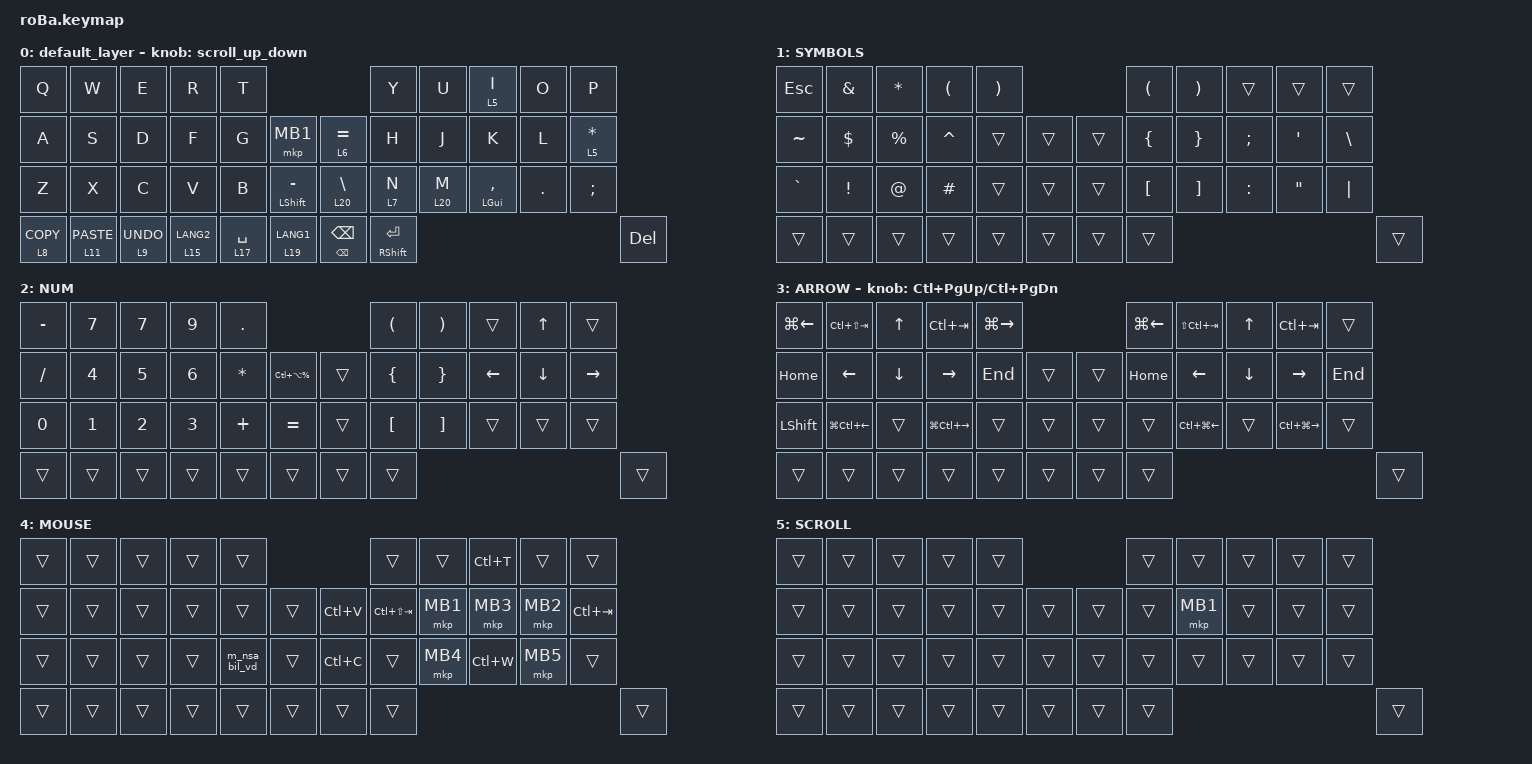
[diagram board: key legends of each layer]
#include <behaviors.dtsi>
#include <dt-bindings/zmk/bt.h>
#include <dt-bindings/zmk/keys.h>
#include <dt-bindings/zmk/pointing.h>

#undef ZMK_POINTING_DEFAULT_SCRL_VAL

#define ZMK_POINTING_DEFAULT_SCRL_VAL 100
#define MOUSE 4
#define SCROLL 5
#define NUM 6

&mt {
    flavor = "hold-preferred";
    quick-tap-ms = <200>;
};

&sl { release-after-ms = <250>; };

&trackball {
    automouse-layer = <4>;
    scroll-layers = <5>;
};

/ {
    combos {
        compatible = "zmk,combos";

        BT0 {
            bindings = <&bt BT_SEL 0>;
            key-positions = <28>;
        };

        BT1 {
            bindings = <&bt BT_SEL 1>;
            key-positions = <28 23>;
        };

        BT2 {
            bindings = <&bt BT_SEL 2>;
            key-positions = <28 24>;
        };

        combo_nsaffricate {
            timeout-ms = <150>;
            key-positions = <34 36>;
            bindings = <&ipa_sw 10 0>;
        };

        combo_saffricate {
            timeout-ms = <150>;
            key-positions = <34 35>;
            bindings = <&ipa_sw 12 0>;
        };

        combo_lfricative {
            timeout-ms = <150>;
            key-positions = <35 41>;
            bindings = <&ipa_sw 13 0>;
        };

        combo_laffricate {
            timeout-ms = <150>;
            key-positions = <34 35 41>;
            bindings = <&ipa_sw 14 0>;
        };

        combo_lapproximant {
            timeout-ms = <150>;
            key-positions = <37 41>;
            bindings = <&ipa_sw 16 0>;
        };

        combo_ltap {
            timeout-ms = <150>;
            key-positions = <38 41>;
            bindings = <&ipa_sw 18 0>;
        };

        // ==========================================
        // 追加: IPA ダイアクリティック用コンボ
        // ==========================================

        combo_SLA {
            timeout-ms = <300>;
            key-positions = <11 20 10>;
            bindings = <&mac_ipa_030D>;
        };

        combo_SLB {
            timeout-ms = <300>;
            key-positions = <11 20 26>;
            bindings = <&mac_ipa_0329>;
        };

        combo_NSA {
            timeout-ms = <300>;
            key-positions = <29 11 10>;
            bindings = <&mac_ipa_0311>;
        };

        combo_NSB {
            timeout-ms = <300>;
            key-positions = <29 11 26>;
            bindings = <&mac_ipa_032F>;
        };

        combo_HL {
            timeout-ms = <300>;
            key-positions = <17 20>;
            bindings = <&mac_ipa_02B0>;
        };

        combo_HHL {
            timeout-ms = <300>;
            key-positions = <17 17 20>;
            bindings = <&mac_ipa_02B1>;
        };

        combo_ML {
            timeout-ms = <300>;
            key-positions = <30 20>;
            bindings = <&mac_ipa_1D4D>;
        };

        combo_NL {
            timeout-ms = <300>;
            key-positions = <29 20>;
            bindings = <&mac_ipa_207F>;
        };

        combo_RNL {
            timeout-ms = <300>;
            key-positions = <3 29 20>;
            bindings = <&mac_ipa_1DAF>;
        };

        combo_GNL {
            timeout-ms = <300>;
            key-positions = <14 29 20>;
            bindings = <&mac_ipa_1DAE>;
        };

        combo_NGL {
            timeout-ms = <300>;
            key-positions = <29 14 20>;
            bindings = <&mac_ipa_1D51>;
        };

        combo_LL {
            timeout-ms = <300>;
            key-positions = <20 20>;
            bindings = <&mac_ipa_02E1>;
        };

        combo_AWL {
            timeout-ms = <300>;
            key-positions = <10 1 20>;
            bindings = <&mac_ipa_1D4A>;
        };

        combo_THL {
            timeout-ms = <300>;
            key-positions = <4 17 20>;
            bindings = <&mac_ipa_1DBF>;
        };

        combo_XL {
            timeout-ms = <300>;
            key-positions = <23 20>;
            bindings = <&mac_ipa_02E3>;
        };

        combo_AP {
            timeout-ms = <300>;
            key-positions = <10 9>;
            bindings = <&mac_ipa_031A>;
        };

        combo_VLA {
            timeout-ms = <300>;
            key-positions = <25 20 10>;
            bindings = <&mac_ipa_030A>;
        };

        combo_VLB {
            timeout-ms = <300>;
            key-positions = <25 20 26>;
            bindings = <&mac_ipa_0325>;
        };

        combo_VD {
            timeout-ms = <300>;
            key-positions = <25 12>;
            bindings = <&mac_ipa_032C>;
        };

        combo_TR {
            timeout-ms = <300>;
            key-positions = <4 3>;
            bindings = <&mac_ipa_0308>;
        };

        combo_TRB {
            timeout-ms = <300>;
            key-positions = <4 3 26>;
            bindings = <&mac_ipa_0324>;
        };

        combo_CT {
            timeout-ms = <300>;
            key-positions = <24 4>;
            bindings = <&mac_ipa_0308>;
        };

        combo_BVD {
            timeout-ms = <300>;
            key-positions = <26 25 12>;
            bindings = <&mac_ipa_0324>;
        };

        combo_TLA {
            timeout-ms = <300>;
            key-positions = <4 20 10>;
            bindings = <&mac_ipa_0303>;
        };

        combo_TLB {
            timeout-ms = <300>;
            key-positions = <4 20 26>;
            bindings = <&mac_ipa_0330>;
        };

        combo_NS {
            timeout-ms = <300>;
            key-positions = <29 11>;
            bindings = <&mac_ipa_0303>;
        };

        combo_CK {
            timeout-ms = <300>;
            key-positions = <24 19>;
            bindings = <&mac_ipa_0330>;
        };

        combo_DT_1 {
            timeout-ms = <300>;
            key-positions = <12 4>;
            bindings = <&mac_ipa_032A>;
        };

        combo_AC_1 {
            timeout-ms = <300>;
            key-positions = <10 24>;
            bindings = <&mac_ipa_033A>;
        };

        combo_FR {
            timeout-ms = <300>;
            key-positions = <13 3>;
            bindings = <&mac_ipa_031F>;
        };

        combo_BK {
            timeout-ms = <300>;
            key-positions = <26 19>;
            bindings = <&mac_ipa_0320>;
        };

        combo_PS {
            timeout-ms = <300>;
            key-positions = <9 11>;
            bindings = <&mac_ipa_031D>;
        };

        combo_DW {
            timeout-ms = <300>;
            key-positions = <12 1>;
            bindings = <&mac_ipa_031E>;
        };

        combo_LN {
            timeout-ms = <300>;
            key-positions = <20 29>;
            bindings = <&mac_ipa_033B>;
        };

        combo_LG {
            timeout-ms = <300>;
            key-positions = <20 14>;
            bindings = <&mac_ipa_033C>;
        };

        combo_MDC {
            timeout-ms = <300>;
            key-positions = <30 12 24>;
            bindings = <&mac_ipa_033D>;
        };

        combo_RDA {
            timeout-ms = <300>;
            key-positions = <3 12 10>;
            bindings = <&mac_ipa_0357>;
        };

        combo_RDB_1 {
            timeout-ms = <300>;
            key-positions = <3 12 26>;
            bindings = <&mac_ipa_0339>;
        };

        combo_URA {
            timeout-ms = <300>;
            key-positions = <6 3 10>;
            bindings = <&mac_ipa_0351>;
        };

        combo_URB {
            timeout-ms = <300>;
            key-positions = <6 3 26>;
            bindings = <&mac_ipa_031C>;
        };

        combo_WL {
            timeout-ms = <300>;
            key-positions = <1 20>;
            bindings = <&mac_ipa_02B7>;
        };

        combo_VL {
            timeout-ms = <300>;
            key-positions = <25 20>;
            bindings = <&mac_ipa_02E0>;
        };

        combo_GML {
            timeout-ms = <300>;
            key-positions = <14 30 20>;
            bindings = <&mac_ipa_02E0>;
        };

        combo_AL {
            timeout-ms = <300>;
            key-positions = <10 20>;
            bindings = <&mac_ipa_02E4>;
        };

        combo_HML {
            timeout-ms = <300>;
            key-positions = <17 30 20>;
            bindings = <&mac_ipa_02C0>;
        };

        combo_ATR {
            timeout-ms = <300>;
            key-positions = <10 4 3>;
            bindings = <&mac_ipa_0318>;
        };

        combo_RTR {
            timeout-ms = <300>;
            key-positions = <3 4 3>;
            bindings = <&mac_ipa_0319>;
        };

        combo_JL {
            timeout-ms = <300>;
            key-positions = <18 20>;
            bindings = <&mac_ipa_02B2>;
        };

        combo_LV {
            timeout-ms = <300>;
            key-positions = <20 25>;
            bindings = <&mac_ipa_026B>;
        };

        combo_RH {
            timeout-ms = <300>;
            key-positions = <3 17>;
            bindings = <&mac_ipa_02DE>;
        };

        combo_DIB {
            timeout-ms = <300>;
            key-positions = <12 7 26>;
            bindings = <&mac_ipa_0361>;
        };

        combo_DBB {
            timeout-ms = <300>;
            key-positions = <12 26 26>;
            bindings = <&mac_ipa_035C>;
        };

        combo_SP {
            timeout-ms = <300>;
            key-positions = <11 9>;
            bindings = <&mac_ipa_02C8>;
        };

        combo_SS {
            timeout-ms = <300>;
            key-positions = <11 11>;
            bindings = <&mac_ipa_02CC>;
        };

        combo_QQ {
            timeout-ms = <300>;
            key-positions = <0 0>;
            bindings = <&mac_ipa_02D0>;
        };

        combo_QQQ {
            timeout-ms = <300>;
            key-positions = <0 0 0>;
            bindings = <&mac_ipa_02D1>;
        };

        combo_FLA {
            timeout-ms = <300>;
            key-positions = <13 20 10>;
            bindings = <&mac_ipa_0306>;
        };

        combo_FLB {
            timeout-ms = <300>;
            key-positions = <13 20 26>;
            bindings = <&mac_ipa_032E>;
        };

        combo_BR {
            timeout-ms = <300>;
            key-positions = <26 3>;
            bindings = <&mac_ipa_0306>;
        };

        combo_BRB {
            timeout-ms = <300>;
            key-positions = <26 3 26>;
            bindings = <&mac_ipa_032E>;
        };

        combo_LK {
            timeout-ms = <300>;
            key-positions = <20 19>;
            bindings = <&mac_ipa_203F>;
        };

        combo_FB {
            timeout-ms = <300>;
            key-positions = <13 26>;
            bindings = <&mac_ipa_007C>;
        };

        combo_IB_1 {
            timeout-ms = <300>;
            key-positions = <7 26>;
            bindings = <&mac_ipa_2016>;
        };

        combo_GLR {
            timeout-ms = <300>;
            key-positions = <14 20 3>;
            bindings = <&mac_ipa_2197>;
        };

        combo_GLF {
            timeout-ms = <300>;
            key-positions = <14 20 13>;
            bindings = <&mac_ipa_2198>;
        };

        combo_PSS {
            timeout-ms = <300>;
            key-positions = <9 11 11>;
            bindings = <&mac_ipa_A71B>;
        };

        combo_DWS {
            timeout-ms = <300>;
            key-positions = <12 1 11>;
            bindings = <&mac_ipa_A71C>;
        };

        combo_AC_2 {
            timeout-ms = <300>;
            key-positions = <10 24>;
            bindings = <&mac_ipa_0301>;
        };

        combo_DAC {
            timeout-ms = <300>;
            key-positions = <12 10 24>;
            bindings = <&mac_ipa_030B>;
        };

        combo_GR {
            timeout-ms = <300>;
            key-positions = <14 3>;
            bindings = <&mac_ipa_0300>;
        };

        combo_DGR {
            timeout-ms = <300>;
            key-positions = <12 14 3>;
            bindings = <&mac_ipa_030F>;
        };

        combo_LT {
            timeout-ms = <300>;
            key-positions = <20 4>;
            bindings = <&mac_ipa_02E9>;
        };

        combo_HLT {
            timeout-ms = <300>;
            key-positions = <17 20 4>;
            bindings = <&mac_ipa_02E8>;
        };

        combo_MT {
            timeout-ms = <300>;
            key-positions = <30 4>;
            bindings = <&mac_ipa_02E7>;
        };

        combo_HHT {
            timeout-ms = <300>;
            key-positions = <17 17 4>;
            bindings = <&mac_ipa_02E6>;
        };

        combo_HT {
            timeout-ms = <300>;
            key-positions = <17 4>;
            bindings = <&mac_ipa_02E5>;
        };

        combo_MC {
            timeout-ms = <300>;
            key-positions = <30 24>;
            bindings = <&mac_ipa_0304>;
        };

        combo_MCB {
            timeout-ms = <300>;
            key-positions = <30 24 26>;
            bindings = <&mac_ipa_0331>;
        };

        combo_CR {
            timeout-ms = <300>;
            key-positions = <24 3>;
            bindings = <&mac_ipa_0302>;
        };

        combo_CRB {
            timeout-ms = <300>;
            key-positions = <24 3 26>;
            bindings = <&mac_ipa_032D>;
        };

        combo_HC {
            timeout-ms = <300>;
            key-positions = <17 24>;
            bindings = <&mac_ipa_030C>;
        };

        combo_HCB {
            timeout-ms = <300>;
            key-positions = <17 24 26>;
            bindings = <&mac_ipa_032C>;
        };

        combo_CD {
            timeout-ms = <300>;
            key-positions = <24 12>;
            bindings = <&mac_ipa_0327>;
        };

        combo_CM {
            timeout-ms = <300>;
            key-positions = <24 30>;
            bindings = <&mac_ipa_02BB>;
        };

        combo_CMB {
            timeout-ms = <300>;
            key-positions = <24 30 26>;
            bindings = <&mac_ipa_0326>;
        };

        combo_IB_2 {
            timeout-ms = <300>;
            key-positions = <7 26>;
            bindings = <&mac_ipa_0311>;
        };

        combo_IBB {
            timeout-ms = <300>;
            key-positions = <7 26 26>;
            bindings = <&mac_ipa_032F>;
        };

        combo_DT_2 {
            timeout-ms = <300>;
            key-positions = <12 4>;
            bindings = <&mac_ipa_0307>;
        };

        combo_DTB {
            timeout-ms = <300>;
            key-positions = <12 4 26>;
            bindings = <&mac_ipa_0323>;
        };

        combo_HK {
            timeout-ms = <300>;
            key-positions = <17 19>;
            bindings = <&mac_ipa_0309>;
        };

        combo_HR {
            timeout-ms = <300>;
            key-positions = <17 3>;
            bindings = <&mac_ipa_031B>;
        };

        combo_OG {
            timeout-ms = <300>;
            key-positions = <8 14>;
            bindings = <&mac_ipa_0328>;
        };

        combo_RG {
            timeout-ms = <300>;
            key-positions = <3 14>;
            bindings = <&mac_ipa_030A>;
        };

        combo_ST {
            timeout-ms = <300>;
            key-positions = <11 4>;
            bindings = <&mac_ipa_0335>;
        };

        combo_DK {
            timeout-ms = <300>;
            key-positions = <12 19>;
            bindings = <&mac_ipa_309B>;
        };

        combo_HD {
            timeout-ms = <300>;
            key-positions = <17 12>;
            bindings = <&mac_ipa_309C>;
        };

        combo_EJ {
            timeout-ms = <300>;
            key-positions = <2 18>;
            bindings = <&mac_ipa_02BC>;
        };

        combo_NM {
            timeout-ms = <300>;
            key-positions = <29 30>;
            bindings = <&mac_ipa_006E_0361_006D>;
        };

        combo_RNM {
            timeout-ms = <300>;
            key-positions = <3 29 30>;
            bindings = <&mac_ipa_0273_0361_006D>;
        };

        combo_NGM {
            timeout-ms = <300>;
            key-positions = <29 14 30>;
            bindings = <&mac_ipa_014B_0361_006D>;
        };

        combo_TP {
            timeout-ms = <300>;
            key-positions = <4 9>;
            bindings = <&mac_ipa_0074_0361_0070>;
        };

        combo_DB {
            timeout-ms = <300>;
            key-positions = <12 26>;
            bindings = <&mac_ipa_0064_0361_0062>;
        };

        combo_RTP {
            timeout-ms = <300>;
            key-positions = <3 4 9>;
            bindings = <&mac_ipa_0288_0361_0070>;
        };

        combo_RDB_2 {
            timeout-ms = <300>;
            key-positions = <3 12 26>;
            bindings = <&mac_ipa_0256_0361_0062>;
        };

        combo_KP {
            timeout-ms = <300>;
            key-positions = <19 9>;
            bindings = <&mac_ipa_006B_0361_0070>;
        };

        combo_GB {
            timeout-ms = <300>;
            key-positions = <14 26>;
            bindings = <&mac_ipa_0067_0361_0062>;
        };

        combo_QH {
            timeout-ms = <300>;
            key-positions = <0 17>;
            bindings = <&mac_ipa_0071_0361_02A1>;
        };

        combo_QP {
            timeout-ms = <300>;
            key-positions = <0 9>;
            bindings = <&mac_ipa_0071_0361_0070>;
        };

        combo_HYY {
            timeout-ms = <300>;
            key-positions = <17 5 5>;
            bindings = <&mac_ipa_0265_030A>;
        };

        combo_YY {
            timeout-ms = <300>;
            key-positions = <5 5>;
            bindings = <&mac_ipa_0265>;
        };

        combo_HW {
            timeout-ms = <300>;
            key-positions = <17 1>;
            bindings = <&mac_ipa_028D>;
        };

        combo_SJ {
            timeout-ms = <300>;
            key-positions = <11 18>;
            bindings = <&mac_ipa_0267>;
        };

        combo_MKP {
            timeout-ms = <300>;
            key-positions = <30 19 9>;
            bindings = <&mac_ipa_0260_030A_035C_0253_0325>;
        };

        combo_MGB {
            timeout-ms = <300>;
            key-positions = <30 14 26>;
            bindings = <&mac_ipa_0260_0361_0253>;
        };

        // ==========================================
        // IPA m_ and v_ macro combos
        // ==========================================

        // m_ macros: place of articulation + manner of articulation
        combo_m_nas_bil_vl { timeout-ms = <150>; key-positions = <9 29>; bindings = <&m_nas_bil_vl>; };
        combo_m_nas_bil_vd { timeout-ms = <150>; key-positions = <26 29>; bindings = <&m_nas_bil_vd>; };
        combo_m_nas_lab_vl { timeout-ms = <150>; key-positions = <13 29>; bindings = <&m_nas_lab_vl>; };
        combo_m_nas_lab_vd { timeout-ms = <150>; key-positions = <25 29>; bindings = <&m_nas_lab_vd>; };
        combo_m_nas_den_vl { timeout-ms = <150>; key-positions = <4 29>; bindings = <&m_nas_den_vl>; };
        combo_m_nas_den_vd { timeout-ms = <150>; key-positions = <12 29>; bindings = <&m_nas_den_vd>; };
        combo_m_nas_alv_vl { timeout-ms = <150>; key-positions = <11 29>; bindings = <&m_nas_alv_vl>; };
        combo_m_nas_alv_vd { timeout-ms = <150>; key-positions = <22 29>; bindings = <&m_nas_alv_vd>; };
        combo_m_nas_palv_vl { timeout-ms = <150>; key-positions = <23 29>; bindings = <&m_nas_palv_vl>; };
        combo_m_nas_palv_vd { timeout-ms = <150>; key-positions = <18 29>; bindings = <&m_nas_palv_vd>; };
        combo_m_nas_ret_vl { timeout-ms = <150>; key-positions = <20 29>; bindings = <&m_nas_ret_vl>; };
        combo_m_nas_ret_vd { timeout-ms = <150>; key-positions = <27 29>; bindings = <&m_nas_ret_vd>; };
        combo_m_nas_pala_vl { timeout-ms = <150>; key-positions = <24 29>; bindings = <&m_nas_pala_vl>; };
        combo_m_nas_pala_vd { timeout-ms = <150>; key-positions = <5 29>; bindings = <&m_nas_pala_vd>; };
        combo_m_nas_vel_vl { timeout-ms = <150>; key-positions = <19 29>; bindings = <&m_nas_vel_vl>; };
        combo_m_nas_vel_vd { timeout-ms = <150>; key-positions = <14 29>; bindings = <&m_nas_vel_vd>; };
        combo_m_nas_uv_vl { timeout-ms = <150>; key-positions = <0 29>; bindings = <&m_nas_uv_vl>; };
        combo_m_nas_uv_vd { timeout-ms = <150>; key-positions = <3 29>; bindings = <&m_nas_uv_vd>; };

        combo_m_p_bil_vl { timeout-ms = <150>; key-positions = <9 34>; bindings = <&m_p_bil_vl>; };
        combo_m_p_bil_vd { timeout-ms = <150>; key-positions = <26 34>; bindings = <&m_p_bil_vd>; };
        combo_m_p_lab_vl { timeout-ms = <150>; key-positions = <13 34>; bindings = <&m_p_lab_vl>; };
        combo_m_p_lab_vd { timeout-ms = <150>; key-positions = <25 34>; bindings = <&m_p_lab_vd>; };
        combo_m_p_den_vl { timeout-ms = <150>; key-positions = <4 34>; bindings = <&m_p_den_vl>; };
        combo_m_p_den_vd { timeout-ms = <150>; key-positions = <12 34>; bindings = <&m_p_den_vd>; };
        combo_m_p_alv_vl { timeout-ms = <150>; key-positions = <11 34>; bindings = <&m_p_alv_vl>; };
        combo_m_p_alv_vd { timeout-ms = <150>; key-positions = <22 34>; bindings = <&m_p_alv_vd>; };
        combo_m_p_ret_vl { timeout-ms = <150>; key-positions = <20 34>; bindings = <&m_p_ret_vl>; };
        combo_m_p_ret_vd { timeout-ms = <150>; key-positions = <27 34>; bindings = <&m_p_ret_vd>; };
        combo_m_p_pala_vl { timeout-ms = <150>; key-positions = <24 34>; bindings = <&m_p_pala_vl>; };
        combo_m_p_pala_vd { timeout-ms = <150>; key-positions = <5 34>; bindings = <&m_p_pala_vd>; };
        combo_m_p_vel_vl { timeout-ms = <150>; key-positions = <19 34>; bindings = <&m_p_vel_vl>; };
        combo_m_p_vel_vd { timeout-ms = <150>; key-positions = <14 34>; bindings = <&m_p_vel_vd>; };
        combo_m_p_uv_vl { timeout-ms = <150>; key-positions = <0 34>; bindings = <&m_p_uv_vl>; };
        combo_m_p_uv_vd { timeout-ms = <150>; key-positions = <3 34>; bindings = <&m_p_uv_vd>; };
        combo_m_p_epi_vl { timeout-ms = <150>; key-positions = <31 34>; bindings = <&m_p_epi_vl>; };
        combo_m_p_glo_vl { timeout-ms = <150>; key-positions = <33 34>; bindings = <&m_p_glo_vl>; };

        combo_m_nsf_bil_vl { timeout-ms = <150>; key-positions = <9 36>; bindings = <&m_nsf_bil_vl>; };
        combo_m_nsf_bil_vd { timeout-ms = <150>; key-positions = <26 36>; bindings = <&m_nsf_bil_vd>; };
        combo_m_nsf_lab_vl { timeout-ms = <150>; key-positions = <13 36>; bindings = <&m_nsf_lab_vl>; };
        combo_m_nsf_lab_vd { timeout-ms = <150>; key-positions = <25 36>; bindings = <&m_nsf_lab_vd>; };
        combo_m_nsf_den_vl { timeout-ms = <150>; key-positions = <4 36>; bindings = <&m_nsf_den_vl>; };
        combo_m_nsf_den_vd { timeout-ms = <150>; key-positions = <12 36>; bindings = <&m_nsf_den_vd>; };
        combo_m_nsf_alv_vl { timeout-ms = <150>; key-positions = <11 36>; bindings = <&m_nsf_alv_vl>; };
        combo_m_nsf_alv_vd { timeout-ms = <150>; key-positions = <22 36>; bindings = <&m_nsf_alv_vd>; };
        combo_m_nsf_palv_vl { timeout-ms = <150>; key-positions = <23 36>; bindings = <&m_nsf_palv_vl>; };
        combo_m_nsf_palv_vd { timeout-ms = <150>; key-positions = <18 36>; bindings = <&m_nsf_palv_vd>; };
        combo_m_nsf_ret_vl { timeout-ms = <150>; key-positions = <20 36>; bindings = <&m_nsf_ret_vl>; };
        combo_m_nsf_ret_vd { timeout-ms = <150>; key-positions = <27 36>; bindings = <&m_nsf_ret_vd>; };
        combo_m_nsf_pala_vl { timeout-ms = <150>; key-positions = <24 36>; bindings = <&m_nsf_pala_vl>; };
        combo_m_nsf_pala_vd { timeout-ms = <150>; key-positions = <5 36>; bindings = <&m_nsf_pala_vd>; };
        combo_m_nsf_vel_vl { timeout-ms = <150>; key-positions = <19 36>; bindings = <&m_nsf_vel_vl>; };
        combo_m_nsf_vel_vd { timeout-ms = <150>; key-positions = <14 36>; bindings = <&m_nsf_vel_vd>; };
        combo_m_nsf_uv_vl { timeout-ms = <150>; key-positions = <0 36>; bindings = <&m_nsf_uv_vl>; };
        combo_m_nsf_uv_vd { timeout-ms = <150>; key-positions = <3 36>; bindings = <&m_nsf_uv_vd>; };
        combo_m_nsf_epi_vl { timeout-ms = <150>; key-positions = <31 36>; bindings = <&m_nsf_epi_vl>; };
        combo_m_nsf_epi_vd { timeout-ms = <150>; key-positions = <32 36>; bindings = <&m_nsf_epi_vd>; };
        combo_m_nsf_glo_vl { timeout-ms = <150>; key-positions = <33 36>; bindings = <&m_nsf_glo_vl>; };
        combo_m_nsf_glo_vd { timeout-ms = <150>; key-positions = <17 36>; bindings = <&m_nsf_glo_vd>; };

        combo_m_nsa_bil_vl { timeout-ms = <150>; key-positions = <9 34 36>; bindings = <&m_nsa_bil_vl>; };
        combo_m_nsa_bil_vd { timeout-ms = <150>; key-positions = <26 34 36>; bindings = <&m_nsa_bil_vd>; };
        combo_m_nsa_lab_vl { timeout-ms = <150>; key-positions = <13 34 36>; bindings = <&m_nsa_lab_vl>; };
        combo_m_nsa_lab_vd { timeout-ms = <150>; key-positions = <25 34 36>; bindings = <&m_nsa_lab_vd>; };
        combo_m_nsa_den_vl { timeout-ms = <150>; key-positions = <4 34 36>; bindings = <&m_nsa_den_vl>; };
        combo_m_nsa_den_vd { timeout-ms = <150>; key-positions = <12 34 36>; bindings = <&m_nsa_den_vd>; };
        combo_m_nsa_alv_vl { timeout-ms = <150>; key-positions = <11 34 36>; bindings = <&m_nsa_alv_vl>; };
        combo_m_nsa_alv_vd { timeout-ms = <150>; key-positions = <22 34 36>; bindings = <&m_nsa_alv_vd>; };
        combo_m_nsa_palv_vl { timeout-ms = <150>; key-positions = <23 34 36>; bindings = <&m_nsa_palv_vl>; };
        combo_m_nsa_palv_vd { timeout-ms = <150>; key-positions = <18 34 36>; bindings = <&m_nsa_palv_vd>; };
        combo_m_nsa_ret_vl { timeout-ms = <150>; key-positions = <20 34 36>; bindings = <&m_nsa_ret_vl>; };
        combo_m_nsa_ret_vd { timeout-ms = <150>; key-positions = <27 34 36>; bindings = <&m_nsa_ret_vd>; };
        combo_m_nsa_pala_vl { timeout-ms = <150>; key-positions = <24 34 36>; bindings = <&m_nsa_pala_vl>; };
        combo_m_nsa_pala_vd { timeout-ms = <150>; key-positions = <5 34 36>; bindings = <&m_nsa_pala_vd>; };
        combo_m_nsa_vel_vl { timeout-ms = <150>; key-positions = <19 34 36>; bindings = <&m_nsa_vel_vl>; };
        combo_m_nsa_vel_vd { timeout-ms = <150>; key-positions = <14 34 36>; bindings = <&m_nsa_vel_vd>; };
        combo_m_nsa_uv_vl { timeout-ms = <150>; key-positions = <0 34 36>; bindings = <&m_nsa_uv_vl>; };
        combo_m_nsa_uv_vd { timeout-ms = <150>; key-positions = <3 34 36>; bindings = <&m_nsa_uv_vd>; };
        combo_m_nsa_epi_vl { timeout-ms = <150>; key-positions = <31 34 36>; bindings = <&m_nsa_epi_vl>; };
        combo_m_nsa_epi_vd { timeout-ms = <150>; key-positions = <32 34 36>; bindings = <&m_nsa_epi_vd>; };
        combo_m_nsa_glo_vl { timeout-ms = <150>; key-positions = <33 34 36>; bindings = <&m_nsa_glo_vl>; };

        combo_m_sf_den_vl { timeout-ms = <150>; key-positions = <4 35>; bindings = <&m_sf_den_vl>; };
        combo_m_sf_den_vd { timeout-ms = <150>; key-positions = <12 35>; bindings = <&m_sf_den_vd>; };
        combo_m_sf_alv_vl { timeout-ms = <150>; key-positions = <11 35>; bindings = <&m_sf_alv_vl>; };
        combo_m_sf_alv_vd { timeout-ms = <150>; key-positions = <22 35>; bindings = <&m_sf_alv_vd>; };
        combo_m_sf_palv_vl { timeout-ms = <150>; key-positions = <23 35>; bindings = <&m_sf_palv_vl>; };
        combo_m_sf_palv_vd { timeout-ms = <150>; key-positions = <18 35>; bindings = <&m_sf_palv_vd>; };
        combo_m_sf_ret_vl { timeout-ms = <150>; key-positions = <20 35>; bindings = <&m_sf_ret_vl>; };
        combo_m_sf_ret_vd { timeout-ms = <150>; key-positions = <27 35>; bindings = <&m_sf_ret_vd>; };
        combo_m_sf_pala_vl { timeout-ms = <150>; key-positions = <24 35>; bindings = <&m_sf_pala_vl>; };
        combo_m_sf_pala_vd { timeout-ms = <150>; key-positions = <5 35>; bindings = <&m_sf_pala_vd>; };

        combo_m_sa_den_vl { timeout-ms = <150>; key-positions = <4 34 35>; bindings = <&m_sa_den_vl>; };
        combo_m_sa_den_vd { timeout-ms = <150>; key-positions = <12 34 35>; bindings = <&m_sa_den_vd>; };
        combo_m_sa_alv_vl { timeout-ms = <150>; key-positions = <11 34 35>; bindings = <&m_sa_alv_vl>; };
        combo_m_sa_alv_vd { timeout-ms = <150>; key-positions = <22 34 35>; bindings = <&m_sa_alv_vd>; };
        combo_m_sa_palv_vl { timeout-ms = <150>; key-positions = <23 34 35>; bindings = <&m_sa_palv_vl>; };
        combo_m_sa_palv_vd { timeout-ms = <150>; key-positions = <18 34 35>; bindings = <&m_sa_palv_vd>; };
        combo_m_sa_pala_vl { timeout-ms = <150>; key-positions = <24 34 35>; bindings = <&m_sa_pala_vl>; };
        combo_m_sa_pala_vd { timeout-ms = <150>; key-positions = <5 34 35>; bindings = <&m_sa_pala_vd>; };
        combo_m_sa_ret_vl { timeout-ms = <150>; key-positions = <20 34 35>; bindings = <&m_sa_ret_vl>; };
        combo_m_sa_ret_vd { timeout-ms = <150>; key-positions = <27 34 35>; bindings = <&m_sa_ret_vd>; };

        combo_m_lf_den_vl { timeout-ms = <150>; key-positions = <4 35 41>; bindings = <&m_lf_den_vl>; };
        combo_m_lf_den_vd { timeout-ms = <150>; key-positions = <12 35 41>; bindings = <&m_lf_den_vd>; };
        combo_m_lf_alv_vl { timeout-ms = <150>; key-positions = <11 35 41>; bindings = <&m_lf_alv_vl>; };
        combo_m_lf_alv_vd { timeout-ms = <150>; key-positions = <22 35 41>; bindings = <&m_lf_alv_vd>; };
        combo_m_lf_ret_vl { timeout-ms = <150>; key-positions = <20 35 41>; bindings = <&m_lf_ret_vl>; };
        combo_m_lf_ret_vd { timeout-ms = <150>; key-positions = <27 35 41>; bindings = <&m_lf_ret_vd>; };
        combo_m_lf_pala_vl { timeout-ms = <150>; key-positions = <24 35 41>; bindings = <&m_lf_pala_vl>; };
        combo_m_lf_pala_vd { timeout-ms = <150>; key-positions = <5 35 41>; bindings = <&m_lf_pala_vd>; };
        combo_m_lf_vel_vl { timeout-ms = <150>; key-positions = <19 35 41>; bindings = <&m_lf_vel_vl>; };
        combo_m_lf_vel_vd { timeout-ms = <150>; key-positions = <14 35 41>; bindings = <&m_lf_vel_vd>; };

        combo_m_la_alv_vl { timeout-ms = <150>; key-positions = <11 34 35 41>; bindings = <&m_la_alv_vl>; };
        combo_m_la_alv_vd { timeout-ms = <150>; key-positions = <22 34 35 41>; bindings = <&m_la_alv_vd>; };
        combo_m_la_ret_vl { timeout-ms = <150>; key-positions = <20 34 35 41>; bindings = <&m_la_ret_vl>; };
        combo_m_la_ret_vd { timeout-ms = <150>; key-positions = <27 34 35 41>; bindings = <&m_la_ret_vd>; };
        combo_m_la_pala_vl { timeout-ms = <150>; key-positions = <24 34 35 41>; bindings = <&m_la_pala_vl>; };
        combo_m_la_pala_vd { timeout-ms = <150>; key-positions = <5 34 35 41>; bindings = <&m_la_pala_vd>; };
        combo_m_la_vel_vl { timeout-ms = <150>; key-positions = <19 34 35 41>; bindings = <&m_la_vel_vl>; };
        combo_m_la_vel_vd { timeout-ms = <150>; key-positions = <14 34 35 41>; bindings = <&m_la_vel_vd>; };

        combo_m_ap_bil_vd { timeout-ms = <150>; key-positions = <26 37>; bindings = <&m_ap_bil_vd>; };
        combo_m_ap_lab_vd { timeout-ms = <150>; key-positions = <25 37>; bindings = <&m_ap_lab_vd>; };
        combo_m_ap_den_vd { timeout-ms = <150>; key-positions = <12 37>; bindings = <&m_ap_den_vd>; };
        combo_m_ap_alv_vd { timeout-ms = <150>; key-positions = <22 37>; bindings = <&m_ap_alv_vd>; };
        combo_m_ap_palv_vd { timeout-ms = <150>; key-positions = <18 37>; bindings = <&m_ap_palv_vd>; };
        combo_m_ap_ret_vd { timeout-ms = <150>; key-positions = <27 37>; bindings = <&m_ap_ret_vd>; };
        combo_m_ap_pala_vd { timeout-ms = <150>; key-positions = <5 37>; bindings = <&m_ap_pala_vd>; };
        combo_m_ap_vel_vd { timeout-ms = <150>; key-positions = <14 37>; bindings = <&m_ap_vel_vd>; };

        combo_m_lap_den_vd { timeout-ms = <150>; key-positions = <12 37 41>; bindings = <&m_lap_den_vd>; };
        combo_m_lap_alv_vl { timeout-ms = <150>; key-positions = <11 37 41>; bindings = <&m_lap_alv_vl>; };
        combo_m_lap_alv_vd { timeout-ms = <150>; key-positions = <22 37 41>; bindings = <&m_lap_alv_vd>; };
        combo_m_lap_ret_vl { timeout-ms = <150>; key-positions = <20 37 41>; bindings = <&m_lap_ret_vl>; };
        combo_m_lap_ret_vd { timeout-ms = <150>; key-positions = <27 37 41>; bindings = <&m_lap_ret_vd>; };
        combo_m_lap_pala_vl { timeout-ms = <150>; key-positions = <24 37 41>; bindings = <&m_lap_pala_vl>; };
        combo_m_lap_pala_vd { timeout-ms = <150>; key-positions = <5 37 41>; bindings = <&m_lap_pala_vd>; };
        combo_m_lap_vel_vl { timeout-ms = <150>; key-positions = <19 37 41>; bindings = <&m_lap_vel_vl>; };
        combo_m_lap_vel_vd { timeout-ms = <150>; key-positions = <14 37 41>; bindings = <&m_lap_vel_vd>; };
        combo_m_lap_uv_vd { timeout-ms = <150>; key-positions = <3 37 41>; bindings = <&m_lap_uv_vd>; };

        combo_m_tap_lab_vd { timeout-ms = <150>; key-positions = <25 38>; bindings = <&m_tap_lab_vd>; };
        combo_m_tap_alv_vl { timeout-ms = <150>; key-positions = <11 38>; bindings = <&m_tap_alv_vl>; };
        combo_m_tap_alv_vd { timeout-ms = <150>; key-positions = <22 38>; bindings = <&m_tap_alv_vd>; };
        combo_m_tap_ret_vl { timeout-ms = <150>; key-positions = <20 38>; bindings = <&m_tap_ret_vl>; };
        combo_m_tap_ret_vd { timeout-ms = <150>; key-positions = <27 38>; bindings = <&m_tap_ret_vd>; };
        combo_m_tap_uv_vd { timeout-ms = <150>; key-positions = <3 38>; bindings = <&m_tap_uv_vd>; };
        combo_m_tap_epi_vd { timeout-ms = <150>; key-positions = <31 38>; bindings = <&m_tap_epi_vd>; };

        combo_m_ltap_alv_vl { timeout-ms = <150>; key-positions = <11 38 41>; bindings = <&m_ltap_alv_vl>; };
        combo_m_ltap_alv_vd { timeout-ms = <150>; key-positions = <22 38 41>; bindings = <&m_ltap_alv_vd>; };
        combo_m_ltap_ret_vl { timeout-ms = <150>; key-positions = <20 38 41>; bindings = <&m_ltap_ret_vl>; };
        combo_m_ltap_ret_vd { timeout-ms = <150>; key-positions = <27 38 41>; bindings = <&m_ltap_ret_vd>; };
        combo_m_ltap_pala_vd { timeout-ms = <150>; key-positions = <5 38 41>; bindings = <&m_ltap_pala_vd>; };
        combo_m_ltap_vel_vd { timeout-ms = <150>; key-positions = <14 38 41>; bindings = <&m_ltap_vel_vd>; };

        combo_m_tr_bil_vl { timeout-ms = <150>; key-positions = <9 39>; bindings = <&m_tr_bil_vl>; };
        combo_m_tr_bil_vd { timeout-ms = <150>; key-positions = <26 39>; bindings = <&m_tr_bil_vd>; };
        combo_m_tr_alv_vl { timeout-ms = <150>; key-positions = <11 39>; bindings = <&m_tr_alv_vl>; };
        combo_m_tr_alv_vd { timeout-ms = <150>; key-positions = <22 39>; bindings = <&m_tr_alv_vd>; };
        combo_m_tr_palv_vd { timeout-ms = <150>; key-positions = <18 39>; bindings = <&m_tr_palv_vd>; };
        combo_m_tr_ret_vl { timeout-ms = <150>; key-positions = <20 39>; bindings = <&m_tr_ret_vl>; };
        combo_m_tr_ret_vd { timeout-ms = <150>; key-positions = <27 39>; bindings = <&m_tr_ret_vd>; };
        combo_m_tr_uv_vl { timeout-ms = <150>; key-positions = <0 39>; bindings = <&m_tr_uv_vl>; };
        combo_m_tr_uv_vd { timeout-ms = <150>; key-positions = <3 39>; bindings = <&m_tr_uv_vd>; };
        combo_m_tr_epi_vl { timeout-ms = <150>; key-positions = <31 39>; bindings = <&m_tr_epi_vl>; };
        combo_m_tr_epi_vd { timeout-ms = <150>; key-positions = <32 39>; bindings = <&m_tr_epi_vd>; };

        combo_m_im_bil_vl { timeout-ms = <150>; key-positions = <9 30>; bindings = <&m_im_bil_vl>; };
        combo_m_im_bil_vd { timeout-ms = <150>; key-positions = <26 30>; bindings = <&m_im_bil_vd>; };
        combo_m_im_den_vl { timeout-ms = <150>; key-positions = <4 30>; bindings = <&m_im_den_vl>; };
        combo_m_im_alv_vl { timeout-ms = <150>; key-positions = <11 30>; bindings = <&m_im_alv_vl>; };
        combo_m_im_alv_vd { timeout-ms = <150>; key-positions = <22 30>; bindings = <&m_im_alv_vd>; };
        combo_m_im_ret_vl { timeout-ms = <150>; key-positions = <20 30>; bindings = <&m_im_ret_vl>; };
        combo_m_im_ret_vd { timeout-ms = <150>; key-positions = <27 30>; bindings = <&m_im_ret_vd>; };
        combo_m_im_pala_vl { timeout-ms = <150>; key-positions = <24 30>; bindings = <&m_im_pala_vl>; };
        combo_m_im_pala_vd { timeout-ms = <150>; key-positions = <5 30>; bindings = <&m_im_pala_vd>; };
        combo_m_im_vel_vl { timeout-ms = <150>; key-positions = <19 30>; bindings = <&m_im_vel_vl>; };
        combo_m_im_vel_vd { timeout-ms = <150>; key-positions = <14 30>; bindings = <&m_im_vel_vd>; };
        combo_m_im_uv_vd { timeout-ms = <150>; key-positions = <3 30>; bindings = <&m_im_uv_vd>; };

        combo_m_lim_den_vl { timeout-ms = <150>; key-positions = <4 30 41>; bindings = <&m_lim_den_vl>; };

        // v_ macros: openness + frontness/roundedness
        combo_v_cl_fr_un { timeout-ms = <150>; key-positions = <34 7>; bindings = <&v_cl_fr_un>; };
        combo_v_cl_fr_ro { timeout-ms = <150>; key-positions = <34 8>; bindings = <&v_cl_fr_ro>; };
        combo_v_cl_ce_un { timeout-ms = <150>; key-positions = <34 10>; bindings = <&v_cl_ce_un>; };
        combo_v_cl_ce_ro { timeout-ms = <150>; key-positions = <34 1>; bindings = <&v_cl_ce_ro>; };
        combo_v_cl_ba_un { timeout-ms = <150>; key-positions = <34 2>; bindings = <&v_cl_ba_un>; };
        combo_v_cl_ba_ro { timeout-ms = <150>; key-positions = <34 6>; bindings = <&v_cl_ba_ro>; };

        combo_v_nc_fr_un { timeout-ms = <150>; key-positions = <35 7>; bindings = <&v_nc_fr_un>; };
        combo_v_nc_fr_ro { timeout-ms = <150>; key-positions = <35 8>; bindings = <&v_nc_fr_ro>; };
        combo_v_nc_ce_un { timeout-ms = <150>; key-positions = <35 10>; bindings = <&v_nc_ce_un>; };
        combo_v_nc_ce_ro { timeout-ms = <150>; key-positions = <35 1>; bindings = <&v_nc_ce_ro>; };
        combo_v_nc_ba_un { timeout-ms = <150>; key-positions = <35 2>; bindings = <&v_nc_ba_un>; };
        combo_v_nc_ba_ro { timeout-ms = <150>; key-positions = <35 6>; bindings = <&v_nc_ba_ro>; };

        combo_v_cm_fr_un { timeout-ms = <150>; key-positions = <36 7>; bindings = <&v_cm_fr_un>; };
        combo_v_cm_fr_ro { timeout-ms = <150>; key-positions = <36 8>; bindings = <&v_cm_fr_ro>; };
        combo_v_cm_ce_un { timeout-ms = <150>; key-positions = <36 10>; bindings = <&v_cm_ce_un>; };
        combo_v_cm_ce_ro { timeout-ms = <150>; key-positions = <36 1>; bindings = <&v_cm_ce_ro>; };
        combo_v_cm_ba_un { timeout-ms = <150>; key-positions = <36 2>; bindings = <&v_cm_ba_un>; };
        combo_v_cm_ba_ro { timeout-ms = <150>; key-positions = <36 6>; bindings = <&v_cm_ba_ro>; };

        combo_v_mi_fr_un { timeout-ms = <150>; key-positions = <37 7>; bindings = <&v_mi_fr_un>; };
        combo_v_mi_fr_ro { timeout-ms = <150>; key-positions = <37 8>; bindings = <&v_mi_fr_ro>; };
        combo_v_mi_ce_un { timeout-ms = <150>; key-positions = <37 10>; bindings = <&v_mi_ce_un>; };
        combo_v_mi_ce_ro { timeout-ms = <150>; key-positions = <37 1>; bindings = <&v_mi_ce_ro>; };
        combo_v_mi_ba_un { timeout-ms = <150>; key-positions = <37 2>; bindings = <&v_mi_ba_un>; };
        combo_v_mi_ba_ro { timeout-ms = <150>; key-positions = <37 6>; bindings = <&v_mi_ba_ro>; };

        combo_v_om_fr_un { timeout-ms = <150>; key-positions = <38 7>; bindings = <&v_om_fr_un>; };
        combo_v_om_fr_ro { timeout-ms = <150>; key-positions = <38 8>; bindings = <&v_om_fr_ro>; };
        combo_v_om_ce_un { timeout-ms = <150>; key-positions = <38 10>; bindings = <&v_om_ce_un>; };
        combo_v_om_ce_ro { timeout-ms = <150>; key-positions = <38 1>; bindings = <&v_om_ce_ro>; };
        combo_v_om_ba_un { timeout-ms = <150>; key-positions = <38 2>; bindings = <&v_om_ba_un>; };
        combo_v_om_ba_ro { timeout-ms = <150>; key-positions = <38 6>; bindings = <&v_om_ba_ro>; };

        combo_v_no_fr_un { timeout-ms = <150>; key-positions = <39 7>; bindings = <&v_no_fr_un>; };
        combo_v_no_fr_ro { timeout-ms = <150>; key-positions = <39 8>; bindings = <&v_no_fr_ro>; };
        combo_v_no_ce_un { timeout-ms = <150>; key-positions = <39 10>; bindings = <&v_no_ce_un>; };
        combo_v_no_ce_ro { timeout-ms = <150>; key-positions = <39 1>; bindings = <&v_no_ce_ro>; };
        combo_v_no_ba_un { timeout-ms = <150>; key-positions = <39 2>; bindings = <&v_no_ba_un>; };
        combo_v_no_ba_ro { timeout-ms = <150>; key-positions = <39 6>; bindings = <&v_no_ba_ro>; };

        combo_v_op_fr_un { timeout-ms = <150>; key-positions = <28 7>; bindings = <&v_op_fr_un>; };
        combo_v_op_fr_ro { timeout-ms = <150>; key-positions = <28 8>; bindings = <&v_op_fr_ro>; };
        combo_v_op_ce_un { timeout-ms = <150>; key-positions = <28 10>; bindings = <&v_op_ce_un>; };
        combo_v_op_ce_ro { timeout-ms = <150>; key-positions = <28 1>; bindings = <&v_op_ce_ro>; };
        combo_v_op_ba_un { timeout-ms = <150>; key-positions = <28 2>; bindings = <&v_op_ba_un>; };
        combo_v_op_ba_ro { timeout-ms = <150>; key-positions = <28 6>; bindings = <&v_op_ba_ro>; };
    };

    macros {
        // ==========================================
        // IPA ダイアクリティック / 記号用マクロ群
        // ==========================================

        mac_ipa_030D: mac_ipa_030D {
            compatible = "zmk,behavior-macro";
            #binding-cells = <0>;
            wait-ms = <30>;             tap-ms = <30>;
            bindings = <&macro_press &kp LALT>, <&kp U &kp N0 &kp N3 &kp N0 &kp D>, <&macro_release &kp LALT>;
        };

        mac_ipa_0329: mac_ipa_0329 {
            compatible = "zmk,behavior-macro";
            #binding-cells = <0>;
            wait-ms = <30>;             tap-ms = <30>;
            bindings = <&macro_press &kp LALT>, <&kp U &kp N0 &kp N3 &kp N2 &kp N9>, <&macro_release &kp LALT>;
        };

        mac_ipa_0311: mac_ipa_0311 {
            compatible = "zmk,behavior-macro";
            #binding-cells = <0>;
            wait-ms = <30>;             tap-ms = <30>;
            bindings = <&macro_press &kp LALT>, <&kp U &kp N0 &kp N3 &kp N1 &kp N1>, <&macro_release &kp LALT>;
        };

        mac_ipa_032F: mac_ipa_032F {
            compatible = "zmk,behavior-macro";
            #binding-cells = <0>;
            wait-ms = <30>;             tap-ms = <30>;
            bindings = <&macro_press &kp LALT>, <&kp U &kp N0 &kp N3 &kp N2 &kp F>, <&macro_release &kp LALT>;
        };

        mac_ipa_02B0: mac_ipa_02B0 {
            compatible = "zmk,behavior-macro";
            #binding-cells = <0>;
            wait-ms = <30>;             tap-ms = <30>;
            bindings = <&macro_press &kp LALT>, <&kp U &kp N0 &kp N2 &kp B &kp N0>, <&macro_release &kp LALT>;
        };

        mac_ipa_02B1: mac_ipa_02B1 {
            compatible = "zmk,behavior-macro";
            #binding-cells = <0>;
            wait-ms = <30>;             tap-ms = <30>;
            bindings = <&macro_press &kp LALT>, <&kp U &kp N0 &kp N2 &kp B &kp N1>, <&macro_release &kp LALT>;
        };

        mac_ipa_1D4D: mac_ipa_1D4D {
            compatible = "zmk,behavior-macro";
            #binding-cells = <0>;
            wait-ms = <30>;             tap-ms = <30>;
            bindings = <&macro_press &kp LALT>, <&kp U &kp N1 &kp D &kp N4 &kp D>, <&macro_release &kp LALT>;
        };

        mac_ipa_207F: mac_ipa_207F {
            compatible = "zmk,behavior-macro";
            #binding-cells = <0>;
            wait-ms = <30>;             tap-ms = <30>;
            bindings = <&macro_press &kp LALT>, <&kp U &kp N2 &kp N0 &kp N7 &kp F>, <&macro_release &kp LALT>;
        };

        mac_ipa_1DAF: mac_ipa_1DAF {
            compatible = "zmk,behavior-macro";
            #binding-cells = <0>;
            wait-ms = <30>;             tap-ms = <30>;
            bindings = <&macro_press &kp LALT>, <&kp U &kp N1 &kp D &kp A &kp F>, <&macro_release &kp LALT>;
        };

        mac_ipa_1DAE: mac_ipa_1DAE {
            compatible = "zmk,behavior-macro";
            #binding-cells = <0>;
            wait-ms = <30>;             tap-ms = <30>;
            bindings = <&macro_press &kp LALT>, <&kp U &kp N1 &kp D &kp A &kp E>, <&macro_release &kp LALT>;
        };

        mac_ipa_1D51: mac_ipa_1D51 {
            compatible = "zmk,behavior-macro";
            #binding-cells = <0>;
            wait-ms = <30>;             tap-ms = <30>;
            bindings = <&macro_press &kp LALT>, <&kp U &kp N1 &kp D &kp N5 &kp N1>, <&macro_release &kp LALT>;
        };

        mac_ipa_02E1: mac_ipa_02E1 {
            compatible = "zmk,behavior-macro";
            #binding-cells = <0>;
            wait-ms = <30>;             tap-ms = <30>;
            bindings = <&macro_press &kp LALT>, <&kp U &kp N0 &kp N2 &kp E &kp N1>, <&macro_release &kp LALT>;
        };

        mac_ipa_1D4A: mac_ipa_1D4A {
            compatible = "zmk,behavior-macro";
            #binding-cells = <0>;
            wait-ms = <30>;             tap-ms = <30>;
            bindings = <&macro_press &kp LALT>, <&kp U &kp N1 &kp D &kp N4 &kp A>, <&macro_release &kp LALT>;
        };

        mac_ipa_1DBF: mac_ipa_1DBF {
            compatible = "zmk,behavior-macro";
            #binding-cells = <0>;
            wait-ms = <30>;             tap-ms = <30>;
            bindings = <&macro_press &kp LALT>, <&kp U &kp N1 &kp D &kp B &kp F>, <&macro_release &kp LALT>;
        };

        mac_ipa_02E3: mac_ipa_02E3 {
            compatible = "zmk,behavior-macro";
            #binding-cells = <0>;
            wait-ms = <30>;             tap-ms = <30>;
            bindings = <&macro_press &kp LALT>, <&kp U &kp N0 &kp N2 &kp E &kp N3>, <&macro_release &kp LALT>;
        };

        mac_ipa_031A: mac_ipa_031A {
            compatible = "zmk,behavior-macro";
            #binding-cells = <0>;
            wait-ms = <30>;             tap-ms = <30>;
            bindings = <&macro_press &kp LALT>, <&kp U &kp N0 &kp N3 &kp N1 &kp A>, <&macro_release &kp LALT>;
        };

        mac_ipa_030A: mac_ipa_030A {
            compatible = "zmk,behavior-macro";
            #binding-cells = <0>;
            wait-ms = <30>;             tap-ms = <30>;
            bindings = <&macro_press &kp LALT>, <&kp U &kp N0 &kp N3 &kp N0 &kp A>, <&macro_release &kp LALT>;
        };

        mac_ipa_0325: mac_ipa_0325 {
            compatible = "zmk,behavior-macro";
            #binding-cells = <0>;
            wait-ms = <30>;             tap-ms = <30>;
            bindings = <&macro_press &kp LALT>, <&kp U &kp N0 &kp N3 &kp N2 &kp N5>, <&macro_release &kp LALT>;
        };

        mac_ipa_032C: mac_ipa_032C {
            compatible = "zmk,behavior-macro";
            #binding-cells = <0>;
            wait-ms = <30>;             tap-ms = <30>;
            bindings = <&macro_press &kp LALT>, <&kp U &kp N0 &kp N3 &kp N2 &kp C>, <&macro_release &kp LALT>;
        };

        mac_ipa_0308: mac_ipa_0308 {
            compatible = "zmk,behavior-macro";
            #binding-cells = <0>;
            wait-ms = <30>;             tap-ms = <30>;
            bindings = <&macro_press &kp LALT>, <&kp U &kp N0 &kp N3 &kp N0 &kp N8>, <&macro_release &kp LALT>;
        };

        mac_ipa_0324: mac_ipa_0324 {
            compatible = "zmk,behavior-macro";
            #binding-cells = <0>;
            wait-ms = <30>;             tap-ms = <30>;
            bindings = <&macro_press &kp LALT>, <&kp U &kp N0 &kp N3 &kp N2 &kp N4>, <&macro_release &kp LALT>;
        };

        mac_ipa_0303: mac_ipa_0303 {
            compatible = "zmk,behavior-macro";
            #binding-cells = <0>;
            wait-ms = <30>;             tap-ms = <30>;
            bindings = <&macro_press &kp LALT>, <&kp U &kp N0 &kp N3 &kp N0 &kp N3>, <&macro_release &kp LALT>;
        };

        mac_ipa_0330: mac_ipa_0330 {
            compatible = "zmk,behavior-macro";
            #binding-cells = <0>;
            wait-ms = <30>;             tap-ms = <30>;
            bindings = <&macro_press &kp LALT>, <&kp U &kp N0 &kp N3 &kp N3 &kp N0>, <&macro_release &kp LALT>;
        };

        mac_ipa_032A: mac_ipa_032A {
            compatible = "zmk,behavior-macro";
            #binding-cells = <0>;
            wait-ms = <30>;             tap-ms = <30>;
            bindings = <&macro_press &kp LALT>, <&kp U &kp N0 &kp N3 &kp N2 &kp A>, <&macro_release &kp LALT>;
        };

        mac_ipa_033A: mac_ipa_033A {
            compatible = "zmk,behavior-macro";
            #binding-cells = <0>;
            wait-ms = <30>;             tap-ms = <30>;
            bindings = <&macro_press &kp LALT>, <&kp U &kp N0 &kp N3 &kp N3 &kp A>, <&macro_release &kp LALT>;
        };

        mac_ipa_031F: mac_ipa_031F {
            compatible = "zmk,behavior-macro";
            #binding-cells = <0>;
            wait-ms = <30>;             tap-ms = <30>;
            bindings = <&macro_press &kp LALT>, <&kp U &kp N0 &kp N3 &kp N1 &kp F>, <&macro_release &kp LALT>;
        };

        mac_ipa_0320: mac_ipa_0320 {
            compatible = "zmk,behavior-macro";
            #binding-cells = <0>;
            wait-ms = <30>;             tap-ms = <30>;
            bindings = <&macro_press &kp LALT>, <&kp U &kp N0 &kp N3 &kp N2 &kp N0>, <&macro_release &kp LALT>;
        };

        mac_ipa_031D: mac_ipa_031D {
            compatible = "zmk,behavior-macro";
            #binding-cells = <0>;
            wait-ms = <30>;             tap-ms = <30>;
            bindings = <&macro_press &kp LALT>, <&kp U &kp N0 &kp N3 &kp N1 &kp D>, <&macro_release &kp LALT>;
        };

        mac_ipa_031E: mac_ipa_031E {
            compatible = "zmk,behavior-macro";
            #binding-cells = <0>;
            wait-ms = <30>;             tap-ms = <30>;
            bindings = <&macro_press &kp LALT>, <&kp U &kp N0 &kp N3 &kp N1 &kp E>, <&macro_release &kp LALT>;
        };

        mac_ipa_033B: mac_ipa_033B {
            compatible = "zmk,behavior-macro";
            #binding-cells = <0>;
            wait-ms = <30>;             tap-ms = <30>;
            bindings = <&macro_press &kp LALT>, <&kp U &kp N0 &kp N3 &kp N3 &kp B>, <&macro_release &kp LALT>;
        };

        mac_ipa_033C: mac_ipa_033C {
            compatible = "zmk,behavior-macro";
            #binding-cells = <0>;
            wait-ms = <30>;             tap-ms = <30>;
            bindings = <&macro_press &kp LALT>, <&kp U &kp N0 &kp N3 &kp N3 &kp C>, <&macro_release &kp LALT>;
        };

        mac_ipa_033D: mac_ipa_033D {
            compatible = "zmk,behavior-macro";
            #binding-cells = <0>;
            wait-ms = <30>;             tap-ms = <30>;
            bindings = <&macro_press &kp LALT>, <&kp U &kp N0 &kp N3 &kp N3 &kp D>, <&macro_release &kp LALT>;
        };

        mac_ipa_0357: mac_ipa_0357 {
            compatible = "zmk,behavior-macro";
            #binding-cells = <0>;
            wait-ms = <30>;             tap-ms = <30>;
            bindings = <&macro_press &kp LALT>, <&kp U &kp N0 &kp N3 &kp N5 &kp N7>, <&macro_release &kp LALT>;
        };

        mac_ipa_0339: mac_ipa_0339 {
            compatible = "zmk,behavior-macro";
            #binding-cells = <0>;
            wait-ms = <30>;             tap-ms = <30>;
            bindings = <&macro_press &kp LALT>, <&kp U &kp N0 &kp N3 &kp N3 &kp N9>, <&macro_release &kp LALT>;
        };

        mac_ipa_0351: mac_ipa_0351 {
            compatible = "zmk,behavior-macro";
            #binding-cells = <0>;
            wait-ms = <30>;             tap-ms = <30>;
            bindings = <&macro_press &kp LALT>, <&kp U &kp N0 &kp N3 &kp N5 &kp N1>, <&macro_release &kp LALT>;
        };

        mac_ipa_031C: mac_ipa_031C {
            compatible = "zmk,behavior-macro";
            #binding-cells = <0>;
            wait-ms = <30>;             tap-ms = <30>;
            bindings = <&macro_press &kp LALT>, <&kp U &kp N0 &kp N3 &kp N1 &kp C>, <&macro_release &kp LALT>;
        };

        mac_ipa_02B7: mac_ipa_02B7 {
            compatible = "zmk,behavior-macro";
            #binding-cells = <0>;
            wait-ms = <30>;             tap-ms = <30>;
            bindings = <&macro_press &kp LALT>, <&kp U &kp N0 &kp N2 &kp B &kp N7>, <&macro_release &kp LALT>;
        };

        mac_ipa_02E0: mac_ipa_02E0 {
            compatible = "zmk,behavior-macro";
            #binding-cells = <0>;
            wait-ms = <30>;             tap-ms = <30>;
            bindings = <&macro_press &kp LALT>, <&kp U &kp N0 &kp N2 &kp E &kp N0>, <&macro_release &kp LALT>;
        };

        mac_ipa_02E4: mac_ipa_02E4 {
            compatible = "zmk,behavior-macro";
            #binding-cells = <0>;
            wait-ms = <30>;             tap-ms = <30>;
            bindings = <&macro_press &kp LALT>, <&kp U &kp N0 &kp N2 &kp E &kp N4>, <&macro_release &kp LALT>;
        };

        mac_ipa_02C0: mac_ipa_02C0 {
            compatible = "zmk,behavior-macro";
            #binding-cells = <0>;
            wait-ms = <30>;             tap-ms = <30>;
            bindings = <&macro_press &kp LALT>, <&kp U &kp N0 &kp N2 &kp C &kp N0>, <&macro_release &kp LALT>;
        };

        mac_ipa_0318: mac_ipa_0318 {
            compatible = "zmk,behavior-macro";
            #binding-cells = <0>;
            wait-ms = <30>;             tap-ms = <30>;
            bindings = <&macro_press &kp LALT>, <&kp U &kp N0 &kp N3 &kp N1 &kp N8>, <&macro_release &kp LALT>;
        };

        mac_ipa_0319: mac_ipa_0319 {
            compatible = "zmk,behavior-macro";
            #binding-cells = <0>;
            wait-ms = <30>;             tap-ms = <30>;
            bindings = <&macro_press &kp LALT>, <&kp U &kp N0 &kp N3 &kp N1 &kp N9>, <&macro_release &kp LALT>;
        };

        mac_ipa_02B2: mac_ipa_02B2 {
            compatible = "zmk,behavior-macro";
            #binding-cells = <0>;
            wait-ms = <30>;             tap-ms = <30>;
            bindings = <&macro_press &kp LALT>, <&kp U &kp N0 &kp N2 &kp B &kp N2>, <&macro_release &kp LALT>;
        };

        mac_ipa_026B: mac_ipa_026B {
            compatible = "zmk,behavior-macro";
            #binding-cells = <0>;
            wait-ms = <30>;             tap-ms = <30>;
            bindings = <&macro_press &kp LALT>, <&kp U &kp N0 &kp N2 &kp N6 &kp B>, <&macro_release &kp LALT>;
        };

        mac_ipa_02DE: mac_ipa_02DE {
            compatible = "zmk,behavior-macro";
            #binding-cells = <0>;
            wait-ms = <30>;             tap-ms = <30>;
            bindings = <&macro_press &kp LALT>, <&kp U &kp N0 &kp N2 &kp D &kp E>, <&macro_release &kp LALT>;
        };

        mac_ipa_0361: mac_ipa_0361 {
            compatible = "zmk,behavior-macro";
            #binding-cells = <0>;
            wait-ms = <30>;             tap-ms = <30>;
            bindings = <&macro_press &kp LALT>, <&kp U &kp N0 &kp N3 &kp N6 &kp N1>, <&macro_release &kp LALT>;
        };

        mac_ipa_035C: mac_ipa_035C {
            compatible = "zmk,behavior-macro";
            #binding-cells = <0>;
            wait-ms = <30>;             tap-ms = <30>;
            bindings = <&macro_press &kp LALT>, <&kp U &kp N0 &kp N3 &kp N5 &kp C>, <&macro_release &kp LALT>;
        };

        mac_ipa_02C8: mac_ipa_02C8 {
            compatible = "zmk,behavior-macro";
            #binding-cells = <0>;
            wait-ms = <30>;             tap-ms = <30>;
            bindings = <&macro_press &kp LALT>, <&kp U &kp N0 &kp N2 &kp C &kp N8>, <&macro_release &kp LALT>;
        };

        mac_ipa_02CC: mac_ipa_02CC {
            compatible = "zmk,behavior-macro";
            #binding-cells = <0>;
            wait-ms = <30>;             tap-ms = <30>;
            bindings = <&macro_press &kp LALT>, <&kp U &kp N0 &kp N2 &kp C &kp C>, <&macro_release &kp LALT>;
        };

        mac_ipa_02D0: mac_ipa_02D0 {
            compatible = "zmk,behavior-macro";
            #binding-cells = <0>;
            wait-ms = <30>;             tap-ms = <30>;
            bindings = <&macro_press &kp LALT>, <&kp U &kp N0 &kp N2 &kp D &kp N0>, <&macro_release &kp LALT>;
        };

        mac_ipa_02D1: mac_ipa_02D1 {
            compatible = "zmk,behavior-macro";
            #binding-cells = <0>;
            wait-ms = <30>;             tap-ms = <30>;
            bindings = <&macro_press &kp LALT>, <&kp U &kp N0 &kp N2 &kp D &kp N1>, <&macro_release &kp LALT>;
        };

        mac_ipa_0306: mac_ipa_0306 {
            compatible = "zmk,behavior-macro";
            #binding-cells = <0>;
            wait-ms = <30>;             tap-ms = <30>;
            bindings = <&macro_press &kp LALT>, <&kp U &kp N0 &kp N3 &kp N0 &kp N6>, <&macro_release &kp LALT>;
        };

        mac_ipa_032E: mac_ipa_032E {
            compatible = "zmk,behavior-macro";
            #binding-cells = <0>;
            wait-ms = <30>;             tap-ms = <30>;
            bindings = <&macro_press &kp LALT>, <&kp U &kp N0 &kp N3 &kp N2 &kp E>, <&macro_release &kp LALT>;
        };

        mac_ipa_203F: mac_ipa_203F {
            compatible = "zmk,behavior-macro";
            #binding-cells = <0>;
            wait-ms = <30>;             tap-ms = <30>;
            bindings = <&macro_press &kp LALT>, <&kp U &kp N2 &kp N0 &kp N3 &kp F>, <&macro_release &kp LALT>;
        };

        mac_ipa_007C: mac_ipa_007C {
            compatible = "zmk,behavior-macro";
            #binding-cells = <0>;
            wait-ms = <30>;             tap-ms = <30>;
            bindings = <&macro_press &kp LALT>, <&kp U &kp N0 &kp N0 &kp N7 &kp C>, <&macro_release &kp LALT>;
        };

        mac_ipa_2016: mac_ipa_2016 {
            compatible = "zmk,behavior-macro";
            #binding-cells = <0>;
            wait-ms = <30>;             tap-ms = <30>;
            bindings = <&macro_press &kp LALT>, <&kp U &kp N2 &kp N0 &kp N1 &kp N6>, <&macro_release &kp LALT>;
        };

        mac_ipa_2197: mac_ipa_2197 {
            compatible = "zmk,behavior-macro";
            #binding-cells = <0>;
            wait-ms = <30>;             tap-ms = <30>;
            bindings = <&macro_press &kp LALT>, <&kp U &kp N2 &kp N1 &kp N9 &kp N7>, <&macro_release &kp LALT>;
        };

        mac_ipa_2198: mac_ipa_2198 {
            compatible = "zmk,behavior-macro";
            #binding-cells = <0>;
            wait-ms = <30>;             tap-ms = <30>;
            bindings = <&macro_press &kp LALT>, <&kp U &kp N2 &kp N1 &kp N9 &kp N8>, <&macro_release &kp LALT>;
        };

        mac_ipa_A71B: mac_ipa_A71B {
            compatible = "zmk,behavior-macro";
            #binding-cells = <0>;
            wait-ms = <30>;             tap-ms = <30>;
            bindings = <&macro_press &kp LALT>, <&kp U &kp A &kp N7 &kp N1 &kp B>, <&macro_release &kp LALT>;
        };

        mac_ipa_A71C: mac_ipa_A71C {
            compatible = "zmk,behavior-macro";
            #binding-cells = <0>;
            wait-ms = <30>;             tap-ms = <30>;
            bindings = <&macro_press &kp LALT>, <&kp U &kp A &kp N7 &kp N1 &kp C>, <&macro_release &kp LALT>;
        };

        mac_ipa_0301: mac_ipa_0301 {
            compatible = "zmk,behavior-macro";
            #binding-cells = <0>;
            wait-ms = <30>;             tap-ms = <30>;
            bindings = <&macro_press &kp LALT>, <&kp U &kp N0 &kp N3 &kp N0 &kp N1>, <&macro_release &kp LALT>;
        };

        mac_ipa_030B: mac_ipa_030B {
            compatible = "zmk,behavior-macro";
            #binding-cells = <0>;
            wait-ms = <30>;             tap-ms = <30>;
            bindings = <&macro_press &kp LALT>, <&kp U &kp N0 &kp N3 &kp N0 &kp B>, <&macro_release &kp LALT>;
        };

        mac_ipa_0300: mac_ipa_0300 {
            compatible = "zmk,behavior-macro";
            #binding-cells = <0>;
            wait-ms = <30>;             tap-ms = <30>;
            bindings = <&macro_press &kp LALT>, <&kp U &kp N0 &kp N3 &kp N0 &kp N0>, <&macro_release &kp LALT>;
        };

        mac_ipa_030F: mac_ipa_030F {
            compatible = "zmk,behavior-macro";
            #binding-cells = <0>;
            wait-ms = <30>;             tap-ms = <30>;
            bindings = <&macro_press &kp LALT>, <&kp U &kp N0 &kp N3 &kp N0 &kp F>, <&macro_release &kp LALT>;
        };

        mac_ipa_02E9: mac_ipa_02E9 {
            compatible = "zmk,behavior-macro";
            #binding-cells = <0>;
            wait-ms = <30>;             tap-ms = <30>;
            bindings = <&macro_press &kp LALT>, <&kp U &kp N0 &kp N2 &kp E &kp N9>, <&macro_release &kp LALT>;
        };

        mac_ipa_02E8: mac_ipa_02E8 {
            compatible = "zmk,behavior-macro";
            #binding-cells = <0>;
            wait-ms = <30>;             tap-ms = <30>;
            bindings = <&macro_press &kp LALT>, <&kp U &kp N0 &kp N2 &kp E &kp N8>, <&macro_release &kp LALT>;
        };

        mac_ipa_02E7: mac_ipa_02E7 {
            compatible = "zmk,behavior-macro";
            #binding-cells = <0>;
            wait-ms = <30>;             tap-ms = <30>;
            bindings = <&macro_press &kp LALT>, <&kp U &kp N0 &kp N2 &kp E &kp N7>, <&macro_release &kp LALT>;
        };

        mac_ipa_02E6: mac_ipa_02E6 {
            compatible = "zmk,behavior-macro";
            #binding-cells = <0>;
            wait-ms = <30>;             tap-ms = <30>;
            bindings = <&macro_press &kp LALT>, <&kp U &kp N0 &kp N2 &kp E &kp N6>, <&macro_release &kp LALT>;
        };

        mac_ipa_02E5: mac_ipa_02E5 {
            compatible = "zmk,behavior-macro";
            #binding-cells = <0>;
            wait-ms = <30>;             tap-ms = <30>;
            bindings = <&macro_press &kp LALT>, <&kp U &kp N0 &kp N2 &kp E &kp N5>, <&macro_release &kp LALT>;
        };

        mac_ipa_0304: mac_ipa_0304 {
            compatible = "zmk,behavior-macro";
            #binding-cells = <0>;
            wait-ms = <30>;             tap-ms = <30>;
            bindings = <&macro_press &kp LALT>, <&kp U &kp N0 &kp N3 &kp N0 &kp N4>, <&macro_release &kp LALT>;
        };

        mac_ipa_0331: mac_ipa_0331 {
            compatible = "zmk,behavior-macro";
            #binding-cells = <0>;
            wait-ms = <30>;             tap-ms = <30>;
            bindings = <&macro_press &kp LALT>, <&kp U &kp N0 &kp N3 &kp N3 &kp N1>, <&macro_release &kp LALT>;
        };

        mac_ipa_0302: mac_ipa_0302 {
            compatible = "zmk,behavior-macro";
            #binding-cells = <0>;
            wait-ms = <30>;             tap-ms = <30>;
            bindings = <&macro_press &kp LALT>, <&kp U &kp N0 &kp N3 &kp N0 &kp N2>, <&macro_release &kp LALT>;
        };

        mac_ipa_032D: mac_ipa_032D {
            compatible = "zmk,behavior-macro";
            #binding-cells = <0>;
            wait-ms = <30>;             tap-ms = <30>;
            bindings = <&macro_press &kp LALT>, <&kp U &kp N0 &kp N3 &kp N2 &kp D>, <&macro_release &kp LALT>;
        };

        mac_ipa_030C: mac_ipa_030C {
            compatible = "zmk,behavior-macro";
            #binding-cells = <0>;
            wait-ms = <30>;             tap-ms = <30>;
            bindings = <&macro_press &kp LALT>, <&kp U &kp N0 &kp N3 &kp N0 &kp C>, <&macro_release &kp LALT>;
        };

        mac_ipa_0327: mac_ipa_0327 {
            compatible = "zmk,behavior-macro";
            #binding-cells = <0>;
            wait-ms = <30>;             tap-ms = <30>;
            bindings = <&macro_press &kp LALT>, <&kp U &kp N0 &kp N3 &kp N2 &kp N7>, <&macro_release &kp LALT>;
        };

        mac_ipa_02BB: mac_ipa_02BB {
            compatible = "zmk,behavior-macro";
            #binding-cells = <0>;
            wait-ms = <30>;             tap-ms = <30>;
            bindings = <&macro_press &kp LALT>, <&kp U &kp N0 &kp N2 &kp B &kp B>, <&macro_release &kp LALT>;
        };

        mac_ipa_0326: mac_ipa_0326 {
            compatible = "zmk,behavior-macro";
            #binding-cells = <0>;
            wait-ms = <30>;             tap-ms = <30>;
            bindings = <&macro_press &kp LALT>, <&kp U &kp N0 &kp N3 &kp N2 &kp N6>, <&macro_release &kp LALT>;
        };

        mac_ipa_0307: mac_ipa_0307 {
            compatible = "zmk,behavior-macro";
            #binding-cells = <0>;
            wait-ms = <30>;             tap-ms = <30>;
            bindings = <&macro_press &kp LALT>, <&kp U &kp N0 &kp N3 &kp N0 &kp N7>, <&macro_release &kp LALT>;
        };

        mac_ipa_0323: mac_ipa_0323 {
            compatible = "zmk,behavior-macro";
            #binding-cells = <0>;
            wait-ms = <30>;             tap-ms = <30>;
            bindings = <&macro_press &kp LALT>, <&kp U &kp N0 &kp N3 &kp N2 &kp N3>, <&macro_release &kp LALT>;
        };

        mac_ipa_0309: mac_ipa_0309 {
            compatible = "zmk,behavior-macro";
            #binding-cells = <0>;
            wait-ms = <30>;             tap-ms = <30>;
            bindings = <&macro_press &kp LALT>, <&kp U &kp N0 &kp N3 &kp N0 &kp N9>, <&macro_release &kp LALT>;
        };

        mac_ipa_031B: mac_ipa_031B {
            compatible = "zmk,behavior-macro";
            #binding-cells = <0>;
            wait-ms = <30>;             tap-ms = <30>;
            bindings = <&macro_press &kp LALT>, <&kp U &kp N0 &kp N3 &kp N1 &kp B>, <&macro_release &kp LALT>;
        };

        mac_ipa_0328: mac_ipa_0328 {
            compatible = "zmk,behavior-macro";
            #binding-cells = <0>;
            wait-ms = <30>;             tap-ms = <30>;
            bindings = <&macro_press &kp LALT>, <&kp U &kp N0 &kp N3 &kp N2 &kp N8>, <&macro_release &kp LALT>;
        };

        mac_ipa_0335: mac_ipa_0335 {
            compatible = "zmk,behavior-macro";
            #binding-cells = <0>;
            wait-ms = <30>;             tap-ms = <30>;
            bindings = <&macro_press &kp LALT>, <&kp U &kp N0 &kp N3 &kp N3 &kp N5>, <&macro_release &kp LALT>;
        };

        mac_ipa_309B: mac_ipa_309B {
            compatible = "zmk,behavior-macro";
            #binding-cells = <0>;
            wait-ms = <30>;             tap-ms = <30>;
            bindings = <&macro_press &kp LALT>, <&kp U &kp N3 &kp N0 &kp N9 &kp B>, <&macro_release &kp LALT>;
        };

        mac_ipa_309C: mac_ipa_309C {
            compatible = "zmk,behavior-macro";
            #binding-cells = <0>;
            wait-ms = <30>;             tap-ms = <30>;
            bindings = <&macro_press &kp LALT>, <&kp U &kp N3 &kp N0 &kp N9 &kp C>, <&macro_release &kp LALT>;
        };

        mac_ipa_02BC: mac_ipa_02BC {
            compatible = "zmk,behavior-macro";
            #binding-cells = <0>;
            wait-ms = <30>;             tap-ms = <30>;
            bindings = <&macro_press &kp LALT>, <&kp U &kp N0 &kp N2 &kp B &kp C>, <&macro_release &kp LALT>;
        };

        // --- 複合Unicode文字（複数のコードを連続入力） ---

        mac_ipa_006E_0361_006D: m_n_m {
            compatible = "zmk,behavior-macro";
            #binding-cells = <0>;
            wait-ms = <30>;             tap-ms = <30>;
            bindings = <&macro_press &kp LALT>, <&kp U &kp N0 &kp N0 &kp N6 &kp E &kp U &kp N0 &kp N3 &kp N6 &kp N1 &kp U &kp N0 &kp N0 &kp N6 &kp D>, <&macro_release &kp LALT>;
        };

        mac_ipa_0273_0361_006D: m_nr_m {
            compatible = "zmk,behavior-macro";
            #binding-cells = <0>;
            wait-ms = <30>;             tap-ms = <30>;
            bindings = <&macro_press &kp LALT>, <&kp U &kp N0 &kp N2 &kp N7 &kp N3 &kp U &kp N0 &kp N3 &kp N6 &kp N1 &kp U &kp N0 &kp N0 &kp N6 &kp D>, <&macro_release &kp LALT>;
        };

        mac_ipa_014B_0361_006D: m_ng_m {
            compatible = "zmk,behavior-macro";
            #binding-cells = <0>;
            wait-ms = <30>;             tap-ms = <30>;
            bindings = <&macro_press &kp LALT>, <&kp U &kp N0 &kp N1 &kp N4 &kp B &kp U &kp N0 &kp N3 &kp N6 &kp N1 &kp U &kp N0 &kp N0 &kp N6 &kp D>, <&macro_release &kp LALT>;
        };

        mac_ipa_0074_0361_0070: m_t_p {
            compatible = "zmk,behavior-macro";
            #binding-cells = <0>;
            wait-ms = <30>;             tap-ms = <30>;
            bindings = <&macro_press &kp LALT>, <&kp U &kp N0 &kp N0 &kp N7 &kp N4 &kp U &kp N0 &kp N3 &kp N6 &kp N1 &kp U &kp N0 &kp N0 &kp N7 &kp N0>, <&macro_release &kp LALT>;
        };

        mac_ipa_0064_0361_0062: m_d_b {
            compatible = "zmk,behavior-macro";
            #binding-cells = <0>;
            wait-ms = <30>;             tap-ms = <30>;
            bindings = <&macro_press &kp LALT>, <&kp U &kp N0 &kp N0 &kp N6 &kp N4 &kp U &kp N0 &kp N3 &kp N6 &kp N1 &kp U &kp N0 &kp N0 &kp N6 &kp N2>, <&macro_release &kp LALT>;
        };

        mac_ipa_0288_0361_0070: m_tr_p {
            compatible = "zmk,behavior-macro";
            #binding-cells = <0>;
            wait-ms = <30>;             tap-ms = <30>;
            bindings = <&macro_press &kp LALT>, <&kp U &kp N0 &kp N2 &kp N8 &kp N8 &kp U &kp N0 &kp N3 &kp N6 &kp N1 &kp U &kp N0 &kp N0 &kp N7 &kp N0>, <&macro_release &kp LALT>;
        };

        mac_ipa_0256_0361_0062: m_dr_b {
            compatible = "zmk,behavior-macro";
            #binding-cells = <0>;
            wait-ms = <30>;             tap-ms = <30>;
            bindings = <&macro_press &kp LALT>, <&kp U &kp N0 &kp N2 &kp N5 &kp N6 &kp U &kp N0 &kp N3 &kp N6 &kp N1 &kp U &kp N0 &kp N0 &kp N6 &kp N2>, <&macro_release &kp LALT>;
        };

        mac_ipa_006B_0361_0070: m_k_p {
            compatible = "zmk,behavior-macro";
            #binding-cells = <0>;
            wait-ms = <30>;             tap-ms = <30>;
            bindings = <&macro_press &kp LALT>, <&kp U &kp N0 &kp N0 &kp N6 &kp B &kp U &kp N0 &kp N3 &kp N6 &kp N1 &kp U &kp N0 &kp N0 &kp N7 &kp N0>, <&macro_release &kp LALT>;
        };

        mac_ipa_0067_0361_0062: m_g_b {
            compatible = "zmk,behavior-macro";
            #binding-cells = <0>;
            wait-ms = <30>;             tap-ms = <30>;
            bindings = <&macro_press &kp LALT>, <&kp U &kp N0 &kp N0 &kp N6 &kp N7 &kp U &kp N0 &kp N3 &kp N6 &kp N1 &kp U &kp N0 &kp N0 &kp N6 &kp N2>, <&macro_release &kp LALT>;
        };

        mac_ipa_0071_0361_02A1: m_q_a {
            compatible = "zmk,behavior-macro";
            #binding-cells = <0>;
            wait-ms = <30>;             tap-ms = <30>;
            bindings = <&macro_press &kp LALT>, <&kp U &kp N0 &kp N0 &kp N7 &kp N1 &kp U &kp N0 &kp N3 &kp N6 &kp N1 &kp U &kp N0 &kp N2 &kp A &kp N1>, <&macro_release &kp LALT>;
        };

        mac_ipa_0071_0361_0070: m_q_p {
            compatible = "zmk,behavior-macro";
            #binding-cells = <0>;
            wait-ms = <30>;             tap-ms = <30>;
            bindings = <&macro_press &kp LALT>, <&kp U &kp N0 &kp N0 &kp N7 &kp N1 &kp U &kp N0 &kp N3 &kp N6 &kp N1 &kp U &kp N0 &kp N0 &kp N7 &kp N0>, <&macro_release &kp LALT>;
        };

        mac_ipa_0265_030A: m_h_ring {
            compatible = "zmk,behavior-macro";
            #binding-cells = <0>;
            wait-ms = <30>;             tap-ms = <30>;
            bindings = <&macro_press &kp LALT>, <&kp U &kp N0 &kp N2 &kp N6 &kp N5 &kp U &kp N0 &kp N3 &kp N0 &kp A>, <&macro_release &kp LALT>;
        };

        mac_ipa_0265: mac_ipa_0265 {
            compatible = "zmk,behavior-macro";
            #binding-cells = <0>;
            wait-ms = <30>;             tap-ms = <30>;
            bindings = <&macro_press &kp LALT>, <&kp U &kp N0 &kp N2 &kp N6 &kp N5>, <&macro_release &kp LALT>;
        };

        mac_ipa_028D: mac_ipa_028D {
            compatible = "zmk,behavior-macro";
            #binding-cells = <0>;
            wait-ms = <30>;             tap-ms = <30>;
            bindings = <&macro_press &kp LALT>, <&kp U &kp N0 &kp N2 &kp N8 &kp D>, <&macro_release &kp LALT>;
        };

        mac_ipa_0267: mac_ipa_0267 {
            compatible = "zmk,behavior-macro";
            #binding-cells = <0>;
            wait-ms = <30>;             tap-ms = <30>;
            bindings = <&macro_press &kp LALT>, <&kp U &kp N0 &kp N2 &kp N6 &kp N7>, <&macro_release &kp LALT>;
        };

        mac_ipa_0260_030A_035C_0253_0325: m_complex1 {
            compatible = "zmk,behavior-macro";
            #binding-cells = <0>;
            wait-ms = <30>;             tap-ms = <30>;
            bindings = <&macro_press &kp LALT>, <&kp U &kp N0 &kp N2 &kp N6 &kp N0 &kp U &kp N0 &kp N3 &kp N0 &kp A &kp U &kp N0 &kp N3 &kp N5 &kp C &kp U &kp N0 &kp N2 &kp N5 &kp N3 &kp U &kp N0 &kp N3 &kp N2 &kp N5>, <&macro_release &kp LALT>;
        };

        mac_ipa_0260_0361_0253: m_complex2 {
            compatible = "zmk,behavior-macro";
            #binding-cells = <0>;
            wait-ms = <30>;             tap-ms = <30>;
            bindings = <&macro_press &kp LALT>, <&kp U &kp N0 &kp N2 &kp N6 &kp N0 &kp U &kp N0 &kp N3 &kp N6 &kp N1 &kp U &kp N0 &kp N2 &kp N5 &kp N3>, <&macro_release &kp LALT>;
        };

        // --- Layer 7: Nasal (鼻音) ---

        m_nas_bil_vl: m_nas_bil_vl {
            compatible = "zmk,behavior-macro";
            #binding-cells = <0>;
            wait-ms = <30>;             tap-ms = <30>;
            bindings = <&macro_press &kp LALT>, <&kp U &kp N0 &kp N0 &kp N6 &kp D &kp U &kp N0 &kp N3 &kp N2 &kp N5>, <&macro_release &kp LALT>;
        }; // m̥
        m_nas_bil_vd: m_nas_bil_vd {
            compatible = "zmk,behavior-macro";
            #binding-cells = <0>;
            wait-ms = <30>;             tap-ms = <30>;
            bindings = <&macro_press &kp LALT>, <&kp U &kp N0 &kp N0 &kp N6 &kp D>, <&macro_release &kp LALT>;
        }; // m
        m_nas_lab_vl: m_nas_lab_vl {
            compatible = "zmk,behavior-macro";
            #binding-cells = <0>;
            wait-ms = <30>;             tap-ms = <30>;
            bindings = <&macro_press &kp LALT>, <&kp U &kp N0 &kp N2 &kp N7 &kp N1 &kp U &kp N0 &kp N3 &kp N0 &kp A>, <&macro_release &kp LALT>;
        }; // ɱ̊
        m_nas_lab_vd: m_nas_lab_vd {
            compatible = "zmk,behavior-macro";
            #binding-cells = <0>;
            wait-ms = <30>;             tap-ms = <30>;
            bindings = <&macro_press &kp LALT>, <&kp U &kp N0 &kp N2 &kp N7 &kp N1>, <&macro_release &kp LALT>;
        }; // ɱ
        m_nas_den_vl: m_nas_den_vl {
            compatible = "zmk,behavior-macro";
            #binding-cells = <0>;
            wait-ms = <30>;             tap-ms = <30>;
            bindings = <&macro_press &kp LALT>, <&kp U &kp N0 &kp N0 &kp N6 &kp E &kp U &kp N0 &kp N3 &kp N2 &kp A &kp U &kp N0 &kp N3 &kp N0 &kp A>, <&macro_release &kp LALT>;
        }; // n̪̊
        m_nas_den_vd: m_nas_den_vd {
            compatible = "zmk,behavior-macro";
            #binding-cells = <0>;
            wait-ms = <30>;             tap-ms = <30>;
            bindings = <&macro_press &kp LALT>, <&kp U &kp N0 &kp N0 &kp N6 &kp E &kp U &kp N0 &kp N3 &kp N2 &kp A>, <&macro_release &kp LALT>;
        }; // n̪
        m_nas_alv_vl: m_nas_alv_vl {
            compatible = "zmk,behavior-macro";
            #binding-cells = <0>;
            wait-ms = <30>;             tap-ms = <30>;
            bindings = <&macro_press &kp LALT>, <&kp U &kp N0 &kp N0 &kp N6 &kp E &kp U &kp N0 &kp N3 &kp N2 &kp N5>, <&macro_release &kp LALT>;
        }; // n̥
        m_nas_alv_vd: m_nas_alv_vd {
            compatible = "zmk,behavior-macro";
            #binding-cells = <0>;
            wait-ms = <30>;             tap-ms = <30>;
            bindings = <&macro_press &kp LALT>, <&kp U &kp N0 &kp N0 &kp N6 &kp E>, <&macro_release &kp LALT>;
        }; // n
        m_nas_palv_vl: m_nas_palv_vl {
            compatible = "zmk,behavior-macro";
            #binding-cells = <0>;
            wait-ms = <30>;             tap-ms = <30>;
            bindings = <&macro_press &kp LALT>, <&kp U &kp N0 &kp N0 &kp N6 &kp E &kp U &kp N0 &kp N3 &kp N2 &kp N0 &kp U &kp N0 &kp N3 &kp N0 &kp A>, <&macro_release &kp LALT>;
        }; // n̠̊
        m_nas_palv_vd: m_nas_palv_vd {
            compatible = "zmk,behavior-macro";
            #binding-cells = <0>;
            wait-ms = <30>;             tap-ms = <30>;
            bindings = <&macro_press &kp LALT>, <&kp U &kp N0 &kp N0 &kp N6 &kp E &kp U &kp N0 &kp N3 &kp N2 &kp N0>, <&macro_release &kp LALT>;
        }; // n̠
        m_nas_ret_vl: m_nas_ret_vl {
            compatible = "zmk,behavior-macro";
            #binding-cells = <0>;
            wait-ms = <30>;             tap-ms = <30>;
            bindings = <&macro_press &kp LALT>, <&kp U &kp N0 &kp N2 &kp N7 &kp N3 &kp U &kp N0 &kp N3 &kp N0 &kp A>, <&macro_release &kp LALT>;
        }; // ɳ̊
        m_nas_ret_vd: m_nas_ret_vd {
            compatible = "zmk,behavior-macro";
            #binding-cells = <0>;
            wait-ms = <30>;             tap-ms = <30>;
            bindings = <&macro_press &kp LALT>, <&kp U &kp N0 &kp N2 &kp N7 &kp N3>, <&macro_release &kp LALT>;
        }; // ɳ
        m_nas_pala_vl: m_nas_pala_vl {
            compatible = "zmk,behavior-macro";
            #binding-cells = <0>;
            wait-ms = <30>;             tap-ms = <30>;
            bindings = <&macro_press &kp LALT>, <&kp U &kp N0 &kp N2 &kp N7 &kp N2 &kp U &kp N0 &kp N3 &kp N0 &kp A>, <&macro_release &kp LALT>;
        }; // ɲ̊
        m_nas_pala_vd: m_nas_pala_vd {
            compatible = "zmk,behavior-macro";
            #binding-cells = <0>;
            wait-ms = <30>;             tap-ms = <30>;
            bindings = <&macro_press &kp LALT>, <&kp U &kp N0 &kp N2 &kp N7 &kp N2>, <&macro_release &kp LALT>;
        }; // ɲ
        m_nas_vel_vl: m_nas_vel_vl {
            compatible = "zmk,behavior-macro";
            #binding-cells = <0>;
            wait-ms = <30>;             tap-ms = <30>;
            bindings = <&macro_press &kp LALT>, <&kp U &kp N0 &kp N1 &kp N4 &kp B &kp U &kp N0 &kp N3 &kp N0 &kp A>, <&macro_release &kp LALT>;
        }; // ŋ̊
        m_nas_vel_vd: m_nas_vel_vd {
            compatible = "zmk,behavior-macro";
            #binding-cells = <0>;
            wait-ms = <30>;             tap-ms = <30>;
            bindings = <&macro_press &kp LALT>, <&kp U &kp N0 &kp N1 &kp N4 &kp B>, <&macro_release &kp LALT>;
        }; // ŋ
        m_nas_uv_vl: m_nas_uv_vl {
            compatible = "zmk,behavior-macro";
            #binding-cells = <0>;
            wait-ms = <30>;             tap-ms = <30>;
            bindings = <&macro_press &kp LALT>, <&kp U &kp N0 &kp N2 &kp N7 &kp N4 &kp U &kp N0 &kp N3 &kp N2 &kp N5>, <&macro_release &kp LALT>;
        }; // ɴ̥
        m_nas_uv_vd: m_nas_uv_vd {
            compatible = "zmk,behavior-macro";
            #binding-cells = <0>;
            wait-ms = <30>;             tap-ms = <30>;
            bindings = <&macro_press &kp LALT>, <&kp U &kp N0 &kp N2 &kp N7 &kp N4>, <&macro_release &kp LALT>;
        }; // ɴ
        // --- Layer 8: Plosive (破裂音) ---

        m_p_bil_vl: m_p_bil_vl {
            compatible = "zmk,behavior-macro";
            #binding-cells = <0>;
            wait-ms = <30>;
            tap-ms = <30>;
            bindings = <&macro_press &kp LALT>, <&kp N0 &kp N0 &kp N7 &kp N0>, <&macro_release &kp LALT>;
        };

        m_p_bil_vd: m_p_bil_vd {
            compatible = "zmk,behavior-macro";
            #binding-cells = <0>;
            wait-ms = <30>;
            tap-ms = <30>;
            bindings = <&macro_press &kp LALT>, <&kp N0 &kp N0 &kp N6 &kp N2>, <&macro_release &kp LALT>;
        };

        m_p_lab_vl: m_p_lab_vl {
            compatible = "zmk,behavior-macro";
            #binding-cells = <0>;
            wait-ms = <30>;
            tap-ms = <30>;
            bindings = <&macro_press &kp LALT>, <&kp N0 &kp N0 &kp N7 &kp N0 &kp N0 &kp N3 &kp N2 &kp A>, <&macro_release &kp LALT>;
        }; // p̪
        m_p_lab_vd: m_p_lab_vd {
            compatible = "zmk,behavior-macro";
            #binding-cells = <0>;
            wait-ms = <30>;
            tap-ms = <30>;
            bindings = <&macro_press &kp LALT>, <&kp N0 &kp N0 &kp N6 &kp N2 &kp N0 &kp N3 &kp N2 &kp A>, <&macro_release &kp LALT>;
        }; // b̪
        m_p_den_vl: m_p_den_vl {
            compatible = "zmk,behavior-macro";
            #binding-cells = <0>;
            wait-ms = <30>;
            tap-ms = <30>;
            bindings = <&macro_press &kp LALT>, <&kp N0 &kp N0 &kp N7 &kp N4 &kp N0 &kp N3 &kp N2 &kp A>, <&macro_release &kp LALT>;
        }; // t̪
        m_p_den_vd: m_p_den_vd {
            compatible = "zmk,behavior-macro";
            #binding-cells = <0>;
            wait-ms = <30>;
            tap-ms = <30>;
            bindings = <&macro_press &kp LALT>, <&kp N0 &kp N0 &kp N6 &kp N4 &kp N0 &kp N3 &kp N2 &kp A>, <&macro_release &kp LALT>;
        }; // d̪
        m_p_alv_vl: m_p_alv_vl {
            compatible = "zmk,behavior-macro";
            #binding-cells = <0>;
            wait-ms = <30>;
            tap-ms = <30>;
            bindings = <&macro_press &kp LALT>, <&kp N0 &kp N0 &kp N7 &kp N4>, <&macro_release &kp LALT>;
        };

        m_p_alv_vd: m_p_alv_vd {
            compatible = "zmk,behavior-macro";
            #binding-cells = <0>;
            wait-ms = <30>;
            tap-ms = <30>;
            bindings = <&macro_press &kp LALT>, <&kp N0 &kp N0 &kp N6 &kp N4>, <&macro_release &kp LALT>;
        };

        m_p_ret_vl: m_p_ret_vl {
            compatible = "zmk,behavior-macro";
            #binding-cells = <0>;
            wait-ms = <30>;
            tap-ms = <30>;
            bindings = <&macro_press &kp LALT>, <&kp U &kp N0 &kp N2 &kp N8 &kp N8>, <&macro_release &kp LALT>;
        }; // ʈ
        m_p_ret_vd: m_p_ret_vd {
            compatible = "zmk,behavior-macro";
            #binding-cells = <0>;
            wait-ms = <30>;
            tap-ms = <30>;
            bindings = <&macro_press &kp LALT>, <&kp U &kp N0 &kp N2 &kp N5 &kp N6>, <&macro_release &kp LALT>;
        }; // ɖ
        m_p_pala_vl: m_p_pala_vl {
            compatible = "zmk,behavior-macro";
            #binding-cells = <0>;
            wait-ms = <30>;
            tap-ms = <30>;
            bindings = <&macro_press &kp LALT>, <&kp N0 &kp N0 &kp E &kp N7>, <&macro_release &kp LALT>;
        };

        m_p_pala_vd: m_p_pala_vd {
            compatible = "zmk,behavior-macro";
            #binding-cells = <0>;
            wait-ms = <30>;
            tap-ms = <30>;
            bindings = <&macro_press &kp LALT>, <&kp U &kp N0 &kp N2 &kp N5 &kp F>, <&macro_release &kp LALT>;
        }; // ɟ
        m_p_vel_vl: m_p_vel_vl {
            compatible = "zmk,behavior-macro";
            #binding-cells = <0>;
            wait-ms = <30>;
            tap-ms = <30>;
            bindings = <&macro_press &kp LALT>, <&kp N0 &kp N0 &kp N6 &kp B>, <&macro_release &kp LALT>;
        };

        m_p_vel_vd: m_p_vel_vd {
            compatible = "zmk,behavior-macro";
            #binding-cells = <0>;
            wait-ms = <30>;
            tap-ms = <30>;
            bindings = <&macro_press &kp LALT>, <&kp N0 &kp N0 &kp N6 &kp N7>, <&macro_release &kp LALT>;
        };

        m_p_uv_vl: m_p_uv_vl {
            compatible = "zmk,behavior-macro";
            #binding-cells = <0>;
            wait-ms = <30>;
            tap-ms = <30>;
            bindings = <&macro_press &kp LALT>, <&kp N0 &kp N0 &kp N7 &kp N1>, <&macro_release &kp LALT>;
        };

        m_p_uv_vd: m_p_uv_vd {
            compatible = "zmk,behavior-macro";
            #binding-cells = <0>;
            wait-ms = <30>;
            tap-ms = <30>;
            bindings = <&macro_press &kp LALT>, <&kp U &kp N0 &kp N2 &kp N6 &kp N2>, <&macro_release &kp LALT>;
        }; // ɢ
        m_p_epi_vl: m_p_epi_vl {
            compatible = "zmk,behavior-macro";
            #binding-cells = <0>;
            wait-ms = <30>;
            tap-ms = <30>;
            bindings = <&macro_press &kp LALT>, <&kp U &kp N0 &kp N2 &kp A &kp N1>, <&macro_release &kp LALT>;
        }; // ʡ
        m_p_glo_vl: m_p_glo_vl {
            compatible = "zmk,behavior-macro";
            #binding-cells = <0>;
            wait-ms = <30>;
            tap-ms = <30>;
            bindings = <&macro_press &kp LALT>, <&kp U &kp N0 &kp N2 &kp N9 &kp N4>, <&macro_release &kp LALT>;
        }; // ʔ
        // --- Layer 9: Non-sibilant Fricative (非歯擦音摩擦音) ---

        m_nsf_bil_vl: m_nsf_bil_vl {
            compatible = "zmk,behavior-macro";
            #binding-cells = <0>;
            wait-ms = <30>;
            tap-ms = <30>;
            bindings = <&macro_press &kp LALT>, <&kp U &kp N0 &kp N2 &kp N7 &kp N8>, <&macro_release &kp LALT>;
        }; // ɸ
        m_nsf_bil_vd: m_nsf_bil_vd {
            compatible = "zmk,behavior-macro";
            #binding-cells = <0>;
            wait-ms = <30>;
            tap-ms = <30>;
            bindings = <&macro_press &kp LALT>, <&kp U &kp N0 &kp N3 &kp B &kp N2>, <&macro_release &kp LALT>;
        }; // β
        m_nsf_lab_vl: m_nsf_lab_vl {
            compatible = "zmk,behavior-macro";
            #binding-cells = <0>;
            wait-ms = <30>;
            tap-ms = <30>;
            bindings = <&macro_press &kp LALT>, <&kp N0 &kp N0 &kp N6 &kp N6>, <&macro_release &kp LALT>;
        };

        m_nsf_lab_vd: m_nsf_lab_vd {
            compatible = "zmk,behavior-macro";
            #binding-cells = <0>;
            wait-ms = <30>;
            tap-ms = <30>;
            bindings = <&macro_press &kp LALT>, <&kp N0 &kp N0 &kp N7 &kp N6>, <&macro_release &kp LALT>;
        };

        m_nsf_den_vl: m_nsf_den_vl {
            compatible = "zmk,behavior-macro";
            #binding-cells = <0>;
            wait-ms = <30>;
            tap-ms = <30>;
            bindings = <&macro_press &kp LALT>, <&kp U &kp N0 &kp N3 &kp B &kp N8>, <&macro_release &kp LALT>;
        }; // θ
        m_nsf_den_vd: m_nsf_den_vd {
            compatible = "zmk,behavior-macro";
            #binding-cells = <0>;
            wait-ms = <30>;
            tap-ms = <30>;
            bindings = <&macro_press &kp LALT>, <&kp U &kp N0 &kp F &kp N0>, <&macro_release &kp LALT>;
        }; // ð
        m_nsf_alv_vl: m_nsf_alv_vl {
            compatible = "zmk,behavior-macro";
            #binding-cells = <0>;
            wait-ms = <30>;
            tap-ms = <30>;
            bindings = <&macro_press &kp LALT>, <&kp U &kp N0 &kp N3 &kp B &kp N8 &kp U &kp N0 &kp N3 &kp N2 &kp N0>, <&macro_release &kp LALT>;
        }; // θ̠
        m_nsf_alv_vd: m_nsf_alv_vd {
            compatible = "zmk,behavior-macro";
            #binding-cells = <0>;
            wait-ms = <30>;
            tap-ms = <30>;
            bindings = <&macro_press &kp LALT>, <&kp U &kp N0 &kp F &kp N0 &kp U &kp N0 &kp N3 &kp N2 &kp N0>, <&macro_release &kp LALT>;
        }; // ð̠
        m_nsf_palv_vl: m_nsf_palv_vl {
            compatible = "zmk,behavior-macro";
            #binding-cells = <0>;
            wait-ms = <30>;
            tap-ms = <30>;
            bindings = <&macro_press &kp LALT>, <&kp U &kp N0 &kp N2 &kp N7 &kp N9 &kp U &kp N0 &kp N3 &kp N2 &kp N0 &kp U &kp N0 &kp N3 &kp N1 &kp D &kp U &kp N0 &kp N3 &kp N0 &kp A>, <&macro_release &kp LALT>;
        }; // ɹ̠̊˔
        m_nsf_palv_vd: m_nsf_palv_vd {
            compatible = "zmk,behavior-macro";
            #binding-cells = <0>;
            wait-ms = <30>;
            tap-ms = <30>;
            bindings = <&macro_press &kp LALT>, <&kp U &kp N0 &kp N2 &kp N7 &kp N9 &kp U &kp N0 &kp N3 &kp N2 &kp N0 &kp U &kp N0 &kp N3 &kp N1 &kp D>, <&macro_release &kp LALT>;
        }; // ɹ̠˔
        m_nsf_ret_vl: m_nsf_ret_vl {
            compatible = "zmk,behavior-macro";
            #binding-cells = <0>;
            wait-ms = <30>;
            tap-ms = <30>;
            bindings = <&macro_press &kp LALT>, <&kp U &kp N0 &kp N2 &kp N7 &kp B &kp U &kp N0 &kp N3 &kp N0 &kp A &kp U &kp N0 &kp N3 &kp N1 &kp D>, <&macro_release &kp LALT>;
        }; // ɻ̊˔
        m_nsf_ret_vd: m_nsf_ret_vd {
            compatible = "zmk,behavior-macro";
            #binding-cells = <0>;
            wait-ms = <30>;
            tap-ms = <30>;
            bindings = <&macro_press &kp LALT>, <&kp U &kp N0 &kp N2 &kp N7 &kp B &kp U &kp N0 &kp N3 &kp N1 &kp D>, <&macro_release &kp LALT>;
        }; // ɻ̝
        m_nsf_pala_vl: m_nsf_pala_vl {
            compatible = "zmk,behavior-macro";
            #binding-cells = <0>;
            wait-ms = <30>;
            tap-ms = <30>;
            bindings = <&macro_press &kp LALT>, <&kp U &kp N0 &kp E &kp N7>, <&macro_release &kp LALT>;
        }; // ç
        m_nsf_pala_vd: m_nsf_pala_vd {
            compatible = "zmk,behavior-macro";
            #binding-cells = <0>;
            wait-ms = <30>;
            tap-ms = <30>;
            bindings = <&macro_press &kp LALT>, <&kp U &kp N0 &kp N2 &kp N9 &kp D>, <&macro_release &kp LALT>;
        }; // ʝ
        m_nsf_vel_vl: m_nsf_vel_vl {
            compatible = "zmk,behavior-macro";
            #binding-cells = <0>;
            wait-ms = <30>;
            tap-ms = <30>;
            bindings = <&macro_press &kp LALT>, <&kp U &kp N0 &kp N2 &kp N6 &kp 3>, <&macro_release &kp LALT>;
        };

        m_nsf_vel_vd: m_nsf_vel_vd {
            compatible = "zmk,behavior-macro";
            #binding-cells = <0>;
            wait-ms = <30>;
            tap-ms = <30>;
            bindings = <&macro_press &kp LALT>, <&kp U &kp N0 &kp N2 &kp N6 &kp N3>, <&macro_release &kp LALT>;
        }; // ɣ
        m_nsf_uv_vl: m_nsf_uv_vl {
            compatible = "zmk,behavior-macro";
            #binding-cells = <0>;
            wait-ms = <30>;
            tap-ms = <30>;
            bindings = <&macro_press &kp LALT>, <&kp U &kp N0 &kp N3 &kp C &kp N7>, <&macro_release &kp LALT>;
        }; // χ
        m_nsf_uv_vd: m_nsf_uv_vd {
            compatible = "zmk,behavior-macro";
            #binding-cells = <0>;
            wait-ms = <30>;
            tap-ms = <30>;
            bindings = <&macro_press &kp LALT>, <&kp U &kp N0 &kp N2 &kp N8 &kp N1>, <&macro_release &kp LALT>;
        }; // ʁ
        m_nsf_epi_vl: m_nsf_epi_vl {
            compatible = "zmk,behavior-macro";
            #binding-cells = <0>;
            wait-ms = <30>;
            tap-ms = <30>;
            bindings = <&macro_press &kp LALT>, <&kp U &kp N0 &kp N1 &kp N2 &kp N7>, <&macro_release &kp LALT>;
        }; // ħ
        m_nsf_epi_vd: m_nsf_epi_vd {
            compatible = "zmk,behavior-macro";
            #binding-cells = <0>;
            wait-ms = <30>;
            tap-ms = <30>;
            bindings = <&macro_press &kp LALT>, <&kp U &kp N0 &kp N2 &kp N9 &kp N5>, <&macro_release &kp LALT>;
        }; // ʕ
        m_nsf_glo_vl: m_nsf_glo_vl {
            compatible = "zmk,behavior-macro";
            #binding-cells = <0>;
            wait-ms = <30>;
            tap-ms = <30>;
            bindings = <&macro_press &kp LALT>, <&kp U &kp N0 &kp N0 &kp N6 &kp N8>, <&macro_release &kp LALT>;
        };

        m_nsf_glo_vd: m_nsf_glo_vd {
            compatible = "zmk,behavior-macro";
            #binding-cells = <0>;
            wait-ms = <30>;
            tap-ms = <30>;
            bindings = <&macro_press &kp LALT>, <&kp U &kp N0 &kp N2 &kp N6 &kp N6>, <&macro_release &kp LALT>;
        }; // ɦ
        // --- Layer 10: Non-sibilant Affricate (非歯擦音破擦音) ---

        m_nsa_bil_vl: m_nsa_bil_vl {
            compatible = "zmk,behavior-macro";
            #binding-cells = <0>;
            wait-ms = <30>;
            tap-ms = <30>;
            bindings = <&macro_press &kp LALT>, <&kp U &kp N0 &kp N0 &kp N7 &kp N0 &kp U &kp N0 &kp N3 &kp N6 &kp N1 &kp U &kp N0 &kp N2 &kp N7 &kp N8>, <&macro_release &kp LALT>;
        }; // p͡ɸ
        m_nsa_bil_vd: m_nsa_bil_vd {
            compatible = "zmk,behavior-macro";
            #binding-cells = <0>;
            wait-ms = <30>;
            tap-ms = <30>;
            bindings = <&macro_press &kp LALT>, <&kp U &kp N0 &kp N0 &kp N6 &kp N2 &kp U &kp N0 &kp N3 &kp N6 &kp N1 &kp U &kp N0 &kp N3 &kp B &kp N2>, <&macro_release &kp LALT>;
        }; // b͡β
        m_nsa_lab_vl: m_nsa_lab_vl {
            compatible = "zmk,behavior-macro";
            #binding-cells = <0>;
            wait-ms = <30>;
            tap-ms = <30>;
            bindings = <&macro_press &kp LALT>, <&kp U &kp N0 &kp N0 &kp N6 &kp N2 &kp U &kp N0 &kp N3 &kp N2 &kp A &kp U &kp N0 &kp N3 &kp N6 &kp N1 &kp U &kp N0 &kp N0 &kp N6 &kp N6>, <&macro_release &kp LALT>;
        }; // p̪͡f
        m_nsa_lab_vd: m_nsa_lab_vd {
            compatible = "zmk,behavior-macro";
            #binding-cells = <0>;
            wait-ms = <30>;
            tap-ms = <30>;
            bindings = <&macro_press &kp LALT>, <&kp U &kp N0 &kp N0 &kp N6 &kp N2 &kp U &kp N0 &kp N3 &kp N2 &kp A &kp U &kp N0 &kp N3 &kp N6 &kp N1 &kp U &kp N0 &kp N0 &kp N7 &kp N6>, <&macro_release &kp LALT>;
        }; // b̪͡v
        m_nsa_den_vl: m_nsa_den_vl {
            compatible = "zmk,behavior-macro";
            #binding-cells = <0>;
            wait-ms = <30>;
            tap-ms = <30>;
            bindings = <&macro_press &kp LALT>, <&kp U &kp N0 &kp N0 &kp N7 &kp N4 &kp U &kp N0 &kp N3 &kp N2 &kp A &kp U &kp N0 &kp N3 &kp N6 &kp N1 &kp U &kp N0 &kp N3 &kp B &kp N8>, <&macro_release &kp LALT>;
        }; // t̪͡θ
        m_nsa_den_vd: m_nsa_den_vd {
            compatible = "zmk,behavior-macro";
            #binding-cells = <0>;
            wait-ms = <30>;
            tap-ms = <30>;
            bindings = <&macro_press &kp LALT>, <&kp U &kp N0 &kp N0 &kp N6 &kp N4 &kp U &kp N0 &kp N3 &kp N2 &kp A &kp U &kp N0 &kp N3 &kp N6 &kp N1 &kp U &kp N0 &kp F &kp N0>, <&macro_release &kp LALT>;
        }; // d̪͡ð
        m_nsa_alv_vl: m_nsa_alv_vl {
            compatible = "zmk,behavior-macro";
            #binding-cells = <0>;
            wait-ms = <30>;
            tap-ms = <30>;
            bindings = <&macro_press &kp LALT>, <&kp U &kp N0 &kp N0 &kp N7 &kp N4 &kp U &kp N0 &kp N3 &kp N6 &kp N1 &kp U &kp N0 &kp N2 &kp N7 &kp N9 &kp U &kp N0 &kp N3 &kp N1 &kp D &kp U &kp N0 &kp N3 &kp N0 &kp A>, <&macro_release &kp LALT>;
        }; // t͡ɹ̝
        m_nsa_alv_vd: m_nsa_alv_vd {
            compatible = "zmk,behavior-macro";
            #binding-cells = <0>;
            wait-ms = <30>;
            tap-ms = <30>;
            bindings = <&macro_press &kp LALT>, <&kp U &kp N0 &kp N0 &kp N6 &kp N4 &kp U &kp N0 &kp N2 &kp N7 &kp N9 &kp U &kp N0 &kp N3 &kp N1 &kp D>, <&macro_release &kp LALT>;
        }; // d͡ɹ̝
        m_nsa_palv_vl: m_nsa_palv_vl {
            compatible = "zmk,behavior-macro";
            #binding-cells = <0>;
            wait-ms = <30>;
            tap-ms = <30>;
            bindings = <&macro_press &kp LALT>, <&kp U &kp N0 &kp N0 &kp N7 &kp N4 &kp U &kp N0 &kp N3 &kp N2 &kp N0 &kp U &kp N0 &kp N3 &kp N6 &kp N1 &kp U &kp N0 &kp N2 &kp N7 &kp N9 &kp U &kp N0 &kp N3 &kp N2 &kp N0 &kp U &kp N0 &kp N3 &kp N1 &kp D &kp U &kp N0 &kp N3 &kp N0 &kp A>, <&macro_release &kp LALT>;
        }; // t̠͡ɹ̠̊˔
        m_nsa_palv_vd: m_nsa_palv_vd {
            compatible = "zmk,behavior-macro";
            #binding-cells = <0>;
            wait-ms = <30>;
            tap-ms = <30>;
            bindings = <&macro_press &kp LALT> , <&kp U &kp N0 &kp N0 &kp N6 &kp N4 &kp U &kp N0 &kp N3 &kp N2 &kp N0 &kp U &kp N0 &kp N3 &kp N6 &kp N1 &kp U &kp N0 &kp N2 &kp N7 &kp N9 &kp U &kp N0 &kp N3 &kp N2 &kp N0 &kp U &kp N0 &kp N3 &kp N1 &kp D>, <&macro_release &kp LALT>;
        }; // d̠͡ɹ̠˔
        m_nsa_ret_vl: m_nsa_ret_vl {
            compatible = "zmk,behavior-macro";
            #binding-cells = <0>;
            wait-ms = <30>;
            tap-ms = <30>;
            bindings = <&macro_press &kp LALT>, <&kp U &kp N0 &kp N2 &kp N8 &kp N8 &kp U &kp N0 &kp N3 &kp N6 &kp N1 &kp U &kp N0 &kp N2 &kp N7 &kp B &kp U &kp N0 &kp N3 &kp N1 &kp D &kp U &kp N0 &kp N3 &kp N0 &kp A>, <&macro_release &kp LALT>;
        }; // ʈ͡ɻ̊˔
        m_nsa_ret_vd: m_nsa_ret_vd {
            compatible = "zmk,behavior-macro";
            #binding-cells = <0>;
            wait-ms = <30>;
            tap-ms = <30>;
            bindings = <&macro_press &kp LALT>, <&kp U &kp N0 &kp N2 &kp N5 &kp N6 &kp U &kp N0 &kp N3 &kp N6 &kp N1 &kp U &kp N0 &kp N2 &kp N7 &kp B &kp U &kp N0 &kp N3 &kp N1 &kp D>, <&macro_release &kp LALT>;
        }; // ɖ͡ɻ̝
        m_nsa_pala_vl: m_nsa_pala_vl {
            compatible = "zmk,behavior-macro";
            #binding-cells = <0>;
            wait-ms = <30>;
            tap-ms = <30>;
            bindings = <&macro_press &kp LALT>, <&kp U &kp N0 &kp N0 &kp E &kp N7 &kp U &kp N0 &kp N3 &kp N6 &kp N1 &kp U &kp N0 &kp E &kp N7>, <&macro_release &kp LALT>;
        }; // c͡ç
        m_nsa_pala_vd: m_nsa_pala_vd {
            compatible = "zmk,behavior-macro";
            #binding-cells = <0>;
            wait-ms = <30>;
            tap-ms = <30>;
            bindings = <&macro_press &kp LALT>, <&kp U &kp N0 &kp N2 &kp N5 &kp F &kp U &kp N0 &kp N3 &kp N6 &kp N1 &kp U &kp N0 &kp N2 &kp N9 &kp D>, <&macro_release &kp LALT>;
        }; // ɟ͡ʝ
        m_nsa_vel_vl: m_nsa_vel_vl {
            compatible = "zmk,behavior-macro";
            #binding-cells = <0>;
            wait-ms = <30>;
            tap-ms = <30>;
            bindings = <&macro_press &kp LALT>, <&kp U &kp N0 &kp N0 &kp N6 &kp B &kp U &kp N0 &kp N3 &kp N6 &kp N1 &kp U &kp N0 &kp N0 &kp N7 &kp N8>, <&macro_release &kp LALT>;
        }; // k͡x
        m_nsa_vel_vd: m_nsa_vel_vd {
            compatible = "zmk,behavior-macro";
            #binding-cells = <0>;
            wait-ms = <30>;
            tap-ms = <30>;
            bindings = <&macro_press &kp LALT>, <&kp U &kp N0 &kp N0 &kp N6 &kp N7 &kp U &kp N0 &kp N3 &kp N6 &kp N1 &kp U &kp N0 &kp N2 &kp N6 &kp N3>, <&macro_release &kp LALT>;
        }; // g͡ɣ
        m_nsa_uv_vl: m_nsa_uv_vl {
            compatible = "zmk,behavior-macro";
            #binding-cells = <0>;
            wait-ms = <30>;
            tap-ms = <30>;
            bindings = <&macro_press &kp LALT>, <&kp U &kp N0 &kp N0 &kp N7 &kp N1 &kp U &kp N0 &kp N3 &kp N6 &kp N1 &kp U &kp N0 &kp N3 &kp C &kp N7>, <&macro_release &kp LALT>;
        }; // q͡χ
        m_nsa_uv_vd: m_nsa_uv_vd {
            compatible = "zmk,behavior-macro";
            #binding-cells = <0>;
            wait-ms = <30>;
            tap-ms = <30>;
            bindings = <&macro_press &kp LALT>, <&kp U &kp N0 &kp N2 &kp N6 &kp N2 &kp U &kp N0 &kp N3 &kp N6 &kp N1 &kp U &kp N0 &kp N2 &kp N8 &kp N1>, <&macro_release &kp LALT>;
        }; // ɢ͡ʁ
        m_nsa_epi_vl: m_nsa_epi_vl {
            compatible = "zmk,behavior-macro";
            #binding-cells = <0>;
            wait-ms = <30>;
            tap-ms = <30>;
            bindings = <&macro_press &kp LALT>, <&kp N0 &kp N2 &kp A &kp N1 &kp N0 &kp N3 &kp N6 &kp N1 &kp N0 &kp N2 &kp N9 &kp C>, <&macro_release &kp LALT>;
        }; // ʡ̥͡ʜ
        m_nsa_epi_vd: m_nsa_epi_vd {
            compatible = "zmk,behavior-macro";
            #binding-cells = <0>;
            wait-ms = <30>;
            tap-ms = <30>;
            bindings = <&macro_press &kp LALT>, <&kp N0 &kp N2 &kp A &kp N1 &kp N0 &kp N3 &kp N6 &kp N1 &kp N0 &kp N2 &kp A &kp N2>, <&macro_release &kp LALT>;
        }; // ʡ͡ʢ
        m_nsa_glo_vl: m_nsa_glo_vl {
            compatible = "zmk,behavior-macro";
            #binding-cells = <0>;
            wait-ms = <30>;
            tap-ms = <30>;
            bindings = <&macro_press &kp LALT>, <&kp N0 &kp N2 &kp N9 &kp N4 &kp N0 &kp N3 &kp N6 &kp N1 &kp U &kp N0 &kp N0 &kp N6 &kp N8>, <&macro_release &kp LALT>;
        }; // ʔ͡h
        // --- Layer 11: Sibilant Fricative ---

        m_sf_den_vl: m_sf_den_vl {
            compatible = "zmk,behavior-macro";
            #binding-cells = <0>;
            wait-ms = <30>;
            tap-ms = <30>;
            bindings = <&macro_press &kp LALT>, <&kp U &kp N0 &kp N0 &kp N7 &kp N3 &kp U &kp N0 &kp N3 &kp N2 &kp A>, <&macro_release &kp LALT>;
        }; // s̪
        m_sf_den_vd: m_sf_den_vd {
            compatible = "zmk,behavior-macro";
            #binding-cells = <0>;
            wait-ms = <30>;
            tap-ms = <30>;
            bindings = <&macro_press &kp LALT>, <&kp U &kp N0 &kp N0 &kp N7 &kp A &kp U &kp N0 &kp N3 &kp N2 &kp A>, <&macro_release &kp LALT>;
        }; // z̪
        m_sf_alv_vl: m_sf_alv_vl {
            compatible = "zmk,behavior-macro";
            #binding-cells = <0>;
            wait-ms = <30>;
            tap-ms = <30>;
            bindings = <&macro_press &kp LALT>, <&kp U &kp N0 &kp N0 &kp N7 &kp N3>, <&macro_release &kp LALT>;
        }; // s
        m_sf_alv_vd: m_sf_alv_vd {
            compatible = "zmk,behavior-macro";
            #binding-cells = <0>;
            wait-ms = <30>;
            tap-ms = <30>;
            bindings = <&macro_press &kp LALT>, <&kp U &kp N0 &kp N0 &kp N7 &kp A>, <&macro_release &kp LALT>;
        }; // z
        m_sf_palv_vl: m_sf_palv_vl {
            compatible = "zmk,behavior-macro";
            #binding-cells = <0>;
            wait-ms = <30>;
            tap-ms = <30>;
            bindings = <&macro_press &kp LALT>, <&kp U &kp N0 &kp N2 &kp N8 &kp N3>, <&macro_release &kp LALT>;
        }; // ʃ
        m_sf_palv_vd: m_sf_palv_vd {
            compatible = "zmk,behavior-macro";
            #binding-cells = <0>;
            wait-ms = <30>;
            tap-ms = <30>;
            bindings = <&macro_press &kp LALT>, <&kp U &kp N0 &kp N2 &kp N9 &kp N2>, <&macro_release &kp LALT>;
        }; // ʒ
        m_sf_ret_vl: m_sf_ret_vl {
            compatible = "zmk,behavior-macro";
            #binding-cells = <0>;
            wait-ms = <30>;
            tap-ms = <30>;
            bindings = <&macro_press &kp LALT>, <&kp U &kp N0 &kp N2 &kp N8 &kp N2>, <&macro_release &kp LALT>;
        }; // ʂ
        m_sf_ret_vd: m_sf_ret_vd {
            compatible = "zmk,behavior-macro";
            #binding-cells = <0>;
            wait-ms = <30>;
            tap-ms = <30>;
            bindings = <&macro_press &kp LALT>, <&kp U &kp N0 &kp N2 &kp N9 &kp N0>, <&macro_release &kp LALT>;
        }; // ʐ
        m_sf_pala_vl: m_sf_pala_vl {
            compatible = "zmk,behavior-macro";
            #binding-cells = <0>;
            wait-ms = <30>;
            tap-ms = <30>;
            bindings = <&macro_press &kp LALT>, <&kp U &kp N0 &kp N2 &kp N5 &kp N5>, <&macro_release &kp LALT>;
        }; // ɕ
        m_sf_pala_vd: m_sf_pala_vd {
            compatible = "zmk,behavior-macro";
            #binding-cells = <0>;
            wait-ms = <30>;
            tap-ms = <30>;
            bindings = <&macro_press &kp LALT>, <&kp U &kp N0 &kp N2 &kp N9 &kp N1>, <&macro_release &kp LALT>;
        }; // ʑ
        // --- Layer 12: Sibilant Affricate ---

        m_sa_den_vl: m_sa_den_vl {
            compatible = "zmk,behavior-macro";
            #binding-cells = <0>;
            wait-ms = <30>;
            tap-ms = <30>;
            bindings = <&macro_press &kp LALT>, <&kp U &kp N0 &kp N0 &kp N7 &kp N4 &kp U &kp N0 &kp N3 &kp N2 &kp A &kp U &kp N0 &kp N3 &kp N6 &kp N1 &kp U &kp N0 &kp N0 &kp N7 &kp N3 &kp U &kp N0 &kp N3 &kp N2 &kp A>, <&macro_release &kp LALT>;
        };

        m_sa_den_vd: m_sa_den_vd {
            compatible = "zmk,behavior-macro";
            #binding-cells = <0>;
            wait-ms = <30>;
            tap-ms = <30>;
            bindings = <&macro_press &kp LALT>, <&kp U &kp N0 &kp N0 &kp N7 &kp N4 &kp U &kp N0 &kp N3 &kp N2 &kp A &kp U &kp N0 &kp N3 &kp N6 &kp N1 &kp U &kp N0 &kp N0 &kp N7 &kp A &kp U &kp N0 &kp N3 &kp N2 &kp A>, <&macro_release &kp LALT>;
        };

        m_sa_alv_vl: m_sa_alv_vl {
            compatible = "zmk,behavior-macro";
            #binding-cells = <0>;
            wait-ms = <30>;
            tap-ms = <30>;
            bindings = <&macro_press &kp LALT>, <&kp U &kp N0 &kp N0 &kp N7 &kp N4 &kp U &kp N0 &kp N3 &kp N6 &kp N1 &kp U &kp N0 &kp N0 &kp N7 &kp N3>, <&macro_release &kp LALT>;
        };

        m_sa_alv_vd: m_sa_alv_vd {
            compatible = "zmk,behavior-macro";
            #binding-cells = <0>;
            wait-ms = <30>;
            tap-ms = <30>;
            bindings = <&macro_press &kp LALT>, <&kp U &kp N0 &kp N0 &kp N7 &kp N4 &kp U &kp N0 &kp N3 &kp N6 &kp N1 &kp U &kp N0 &kp N0 &kp N7 &kp A>, <&macro_release &kp LALT>;
        };

        m_sa_palv_vl: m_sa_palv_vl {
            compatible = "zmk,behavior-macro";
            #binding-cells = <0>;
            wait-ms = <30>;
            tap-ms = <30>;
            bindings = <&macro_press &kp LALT>, <&kp U &kp N0 &kp N0 &kp N7 &kp N4 &kp U &kp N0 &kp N3 &kp N6 &kp N1 &kp U &kp N0 &kp N2 &kp N8 &kp N3>, <&macro_release &kp LALT>;
        };

        m_sa_palv_vd: m_sa_palv_vd {
            compatible = "zmk,behavior-macro";
            #binding-cells = <0>;
            wait-ms = <30>;
            tap-ms = <30>;
            bindings = <&macro_press &kp LALT>, <&kp U &kp N0 &kp N0 &kp N7 &kp N4 &kp U &kp N0 &kp N3 &kp N6 &kp N1 &kp U &kp N0 &kp N2 &kp N9 &kp N2>, <&macro_release &kp LALT>;
        };

        m_sa_pala_vl: m_sa_pala_vl {
            compatible = "zmk,behavior-macro";
            #binding-cells = <0>;
            wait-ms = <30>;
            tap-ms = <30>;
            bindings = <&macro_press &kp LALT>, <&kp U &kp N0 &kp N0 &kp N7 &kp N4 &kp U &kp N0 &kp N3 &kp N6 &kp N1 &kp U &kp N0 &kp N2 &kp N5 &kp N5>, <&macro_release &kp LALT>;
        }; // t͡ɕ
        m_sa_pala_vd: m_sa_pala_vd {
            compatible = "zmk,behavior-macro";
            #binding-cells = <0>;
            wait-ms = <30>;
            tap-ms = <30>;
            bindings = <&macro_press &kp LALT>, <&kp U &kp N0 &kp N0 &kp N6 &kp N4 &kp U &kp N0 &kp N3 &kp N6 &kp N1 &kp U &kp N0 &kp N2 &kp N9 &kp N1>, <&macro_release &kp LALT>;
        }; // d͡ʑ
        m_sa_ret_vl: m_sa_ret_vl {
            compatible = "zmk,behavior-macro";
            #binding-cells = <0>;
            wait-ms = <30>;
            tap-ms = <30>;
            bindings = <&macro_press &kp LALT>, <&kp U &kp N0 &kp N2 &kp N8 &kp N8 &kp U &kp N0 &kp N3 &kp N6 &kp N1 &kp U &kp N0 &kp N2 &kp N8 &kp N2>, <&macro_release &kp LALT>;
        };

        m_sa_ret_vd: m_sa_ret_vd {
            compatible = "zmk,behavior-macro";
            #binding-cells = <0>;
            wait-ms = <30>;
            tap-ms = <30>;
            bindings = <&macro_press &kp LALT>, <&kp U &kp N0 &kp N2 &kp N5 &kp N6 &kp U &kp N0 &kp N3 &kp N6 &kp N1 &kp U &kp N0 &kp N2 &kp N9 &kp N0>, <&macro_release &kp LALT>;
        };

        // Layer 13: Lateral Fricative

        m_lf_den_vl: m_lf_den_vl {
            compatible = "zmk,behavior-macro";
            #binding-cells = <0>;
            wait-ms = <30>;
            tap-ms = <30>;
            bindings = <&macro_press &kp LALT>, <&kp U &kp N0 &kp N2 &kp N6 &kp C>, <&macro_release &kp LALT>;
        }; // ɬ̪
        m_lf_den_vd: m_lf_den_vd {
            compatible = "zmk,behavior-macro";
            #binding-cells = <0>;
            wait-ms = <30>;
            tap-ms = <30>;
            bindings = <&macro_press &kp LALT>, <&kp U &kp N0 &kp N2 &kp N6 &kp E>, <&macro_release &kp LALT>;
        }; // ɮ̪
        m_lf_alv_vl: m_lf_alv_vl {
            compatible = "zmk,behavior-macro";
            #binding-cells = <0>;
            wait-ms = <30>;
            tap-ms = <30>;
            bindings = <&macro_press &kp LALT>, <&kp U &kp N0 &kp N2 &kp N6 &kp C>, <&macro_release &kp LALT>;
        }; // ɬ
        m_lf_alv_vd: m_lf_alv_vd {
            compatible = "zmk,behavior-macro";
            #binding-cells = <0>;
            wait-ms = <30>;
            tap-ms = <30>;
            bindings = <&macro_press &kp LALT>, <&kp U &kp N0 &kp N2 &kp N6 &kp E>, <&macro_release &kp LALT>;
        }; // ɮ
        m_lf_ret_vl: m_lf_ret_vl {
            compatible = "zmk,behavior-macro";
            #binding-cells = <0>;
            wait-ms = <30>;
            tap-ms = <30>;
            bindings = <&macro_press &kp LALT>, <&kp U &kp N0 &kp N2 &kp N6 &kp D &kp U &kp N0 &kp N3 &kp N1 &kp D &kp U &kp N0 &kp N3 &kp N0 &kp A>, <&macro_release &kp LALT>;
        }; // ɭ̝̊
        m_lf_ret_vd: m_lf_ret_vd {
            compatible = "zmk,behavior-macro";
            #binding-cells = <0>;
            wait-ms = <30>;
            tap-ms = <30>;
            bindings = <&macro_press &kp LALT>, <&kp U &kp N0 &kp N2 &kp N6 &kp D &kp U &kp N0 &kp N3 &kp N1 &kp D>, <&macro_release &kp LALT>;
        }; // ɭ̝
        m_lf_pala_vl: m_lf_pala_vl {
            compatible = "zmk,behavior-macro";
            #binding-cells = <0>;
            wait-ms = <30>;
            tap-ms = <30>;
            bindings = <&macro_press &kp LALT>, <&kp U &kp N0 &kp N2 &kp N8 &kp E>, <&macro_release &kp LALT>;
        }; // ʎ̝̊
        m_lf_pala_vd: m_lf_pala_vd {
            compatible = "zmk,behavior-macro";
            #binding-cells = <0>;
            wait-ms = <30>;
            tap-ms = <30>;
            bindings = <&macro_press &kp LALT>, <&kp U &kp N0 &kp N2 &kp N8 &kp E>, <&macro_release &kp LALT>;
        };

        m_lf_vel_vl: m_lf_vel_vl {
            compatible = "zmk,behavior-macro";
            #binding-cells = <0>;
            wait-ms = <30>;
            tap-ms = <30>;
            bindings = <&macro_press &kp LALT>, <&kp U &kp N0 &kp N2 &kp N9 &kp F>, <&macro_release &kp LALT>;
        }; // ʟ̝̊
        m_lf_vel_vd: m_lf_vel_vd {
            compatible = "zmk,behavior-macro";
            #binding-cells = <0>;
            wait-ms = <30>;
            tap-ms = <30>;
            bindings = <&macro_press &kp LALT>, <&kp U &kp N0 &kp N2 &kp N9 &kp F>, <&macro_release &kp LALT>;
        };

        // --- Layer 14: Lateral Affricate (側面破擦音) ---

        m_la_alv_vl: m_la_alv_vl {
            compatible = "zmk,behavior-macro";
            #binding-cells = <0>;
            wait-ms = <30>;
            tap-ms = <30>;
            bindings = <&macro_press &kp LALT>, <&kp U &kp N0 &kp N0 &kp N7 &kp N4 &kp U &kp N0 &kp N3 &kp N6 &kp N1 &kp U &kp N0 &kp N2 &kp N6 &kp C>, <&macro_release &kp LALT>;
        };

        m_la_alv_vd: m_la_alv_vd {
            compatible = "zmk,behavior-macro";
            #binding-cells = <0>;
            wait-ms = <30>;
            tap-ms = <30>;
            bindings = <&macro_press &kp LALT>, <&kp U &kp N0 &kp N0 &kp N7 &kp N4 &kp U &kp N0 &kp N3 &kp N6 &kp N1 &kp U &kp N0 &kp N2 &kp N9 &kp E>, <&macro_release &kp LALT>;
        };

        m_la_ret_vl: m_la_ret_vl {
            compatible = "zmk,behavior-macro";
            #binding-cells = <0>;
            wait-ms = <30>;
            tap-ms = <30>;
            bindings = <&macro_press &kp LALT>, <&kp U &kp N0 &kp N2 &kp N8 &kp N8 &kp U &kp N0 &kp N3 &kp N6 &kp N1 &kp U &kp N0 &kp N2 &kp N6 &kp D &kp U &kp N0 &kp N3 &kp N1 &kp D &kp U &kp N0 &kp N3 &kp N0 &kp A>, <&macro_release &kp LALT>;
        };

        m_la_ret_vd: m_la_ret_vd {
            compatible = "zmk,behavior-macro";
            #binding-cells = <0>;
            wait-ms = <30>;
            tap-ms = <30>;
            bindings = <&macro_press &kp LALT>, <&kp U &kp N0 &kp N2 &kp N5 &kp N6 &kp U &kp N0 &kp N3 &kp N6 &kp N1 &kp U &kp N0 &kp N2 &kp N6 &kp D &kp U &kp N0 &kp N3 &kp N1 &kp D>, <&macro_release &kp LALT>;
        };

        m_la_pala_vl: m_la_pala_vl {
            compatible = "zmk,behavior-macro";
            #binding-cells = <0>;
            wait-ms = <30>;
            tap-ms = <30>;
            bindings = <&macro_press &kp LALT>, <&kp U &kp N0 &kp N0 &kp N6 &kp N3 &kp U &kp N0 &kp N3 &kp N6 &kp N1 &kp U &kp N0 &kp N2 &kp N8 &kp E &kp U &kp N0 &kp N3 &kp N1 &kp D &kp U &kp N0 &kp N3 &kp N0 &kp A>, <&macro_release &kp LALT>;
        }; // c͡ʎ̝̊
        m_la_pala_vd: m_la_pala_vd {
            compatible = "zmk,behavior-macro";
            #binding-cells = <0>;
            wait-ms = <30>;
            tap-ms = <30>;
            bindings = <&macro_press &kp LALT>, <&kp U &kp N0 &kp N2 &kp N5 &kp F &kp U &kp N0 &kp N3 &kp N6 &kp N1 &kp U &kp N0 &kp N2 &kp N8 &kp E &kp U &kp N0 &kp N3 &kp N1 &kp D>, <&macro_release &kp LALT>;
        }; // ɟ͡ʎ̝
        m_la_vel_vl: m_la_vel_vl {
            compatible = "zmk,behavior-macro";
            #binding-cells = <0>;
            wait-ms = <30>;
            tap-ms = <30>;
            bindings = <&macro_press &kp LALT>, <&kp U &kp N0 &kp N0 &kp N6 &kp B &kp U &kp N0 &kp N3 &kp N6 &kp N1 &kp U &kp N0 &kp N2 &kp N9 &kp F &kp U &kp N0 &kp N3 &kp N1 &kp D &kp U &kp N0 &kp N3 &kp N0 &kp A>, <&macro_release &kp LALT>;
        }; // k͡ʟ̝̊
        m_la_vel_vd: m_la_vel_vd {
            compatible = "zmk,behavior-macro";
            #binding-cells = <0>;
            wait-ms = <30>;
            tap-ms = <30>;
            bindings = <&macro_press &kp LALT>, <&kp U &kp N0 &kp N0 &kp N6 &kp B &kp U &kp N0 &kp N3 &kp N6 &kp N1 &kp U &kp N0 &kp N2 &kp N9 &kp F &kp U &kp N0 &kp N3 &kp N1 &kp D>, <&macro_release &kp LALT>;
        }; // g͡ʟ̝
        // --- Layer 15: Approximant (接近音) ---

        m_ap_bil_vd: m_ap_bil_vd {
            compatible = "zmk,behavior-macro";
            #binding-cells = <0>;
            wait-ms = <30>;
            tap-ms = <30>;
            bindings = <&macro_press &kp LALT>, <&kp U &kp N0 &kp N3 &kp B &kp N2 &kp U &kp N0 &kp N3 &kp N1 &kp E>, <&macro_release &kp LALT>;
        };

        m_ap_lab_vd: m_ap_lab_vd {
            compatible = "zmk,behavior-macro";
            #binding-cells = <0>;
            wait-ms = <30>;
            tap-ms = <30>;
            bindings = <&macro_press &kp LALT>, <&kp U &kp N0 &kp N2 &kp N8 &kp B>, <&macro_release &kp LALT>;
        };

        m_ap_den_vd: m_ap_den_vd {
            compatible = "zmk,behavior-macro";
            #binding-cells = <0>;
            wait-ms = <30>;
            tap-ms = <30>;
            bindings = <&macro_press &kp LALT>, <&kp U &kp N0 &kp N0 &kp F &kp N0 &kp U &kp N0 &kp N3 &kp N1 &kp E>, <&macro_release &kp LALT>;
        };

        m_ap_alv_vd: m_ap_alv_vd {
            compatible = "zmk,behavior-macro";
            #binding-cells = <0>;
            wait-ms = <30>;
            tap-ms = <30>;
            bindings = <&macro_press &kp LALT>, <&kp U &kp N0 &kp N2 &kp N7 &kp N9>, <&macro_release &kp LALT>;
        };

        m_ap_palv_vd: m_ap_palv_vd {
            compatible = "zmk,behavior-macro";
            #binding-cells = <0>;
            wait-ms = <30>;
            tap-ms = <30>;
            bindings = <&macro_press &kp LALT>, <&kp U &kp N0 &kp N2 &kp N7 &kp N9 &kp U &kp N0 &kp N3 &kp N2 &kp N0>, <&macro_release &kp LALT>;
        };

        m_ap_ret_vd: m_ap_ret_vd {
            compatible = "zmk,behavior-macro";
            #binding-cells = <0>;
            wait-ms = <30>;
            tap-ms = <30>;
            bindings = <&macro_press &kp LALT>, <&kp U &kp N0 &kp N2 &kp N7 &kp B>, <&macro_release &kp LALT>;
        };

        m_ap_pala_vd: m_ap_pala_vd {
            compatible = "zmk,behavior-macro";
            #binding-cells = <0>;
            wait-ms = <30>;
            tap-ms = <30>;
            bindings = <&macro_press &kp LALT>, <&kp U &kp N0 &kp N0 &kp N6 &kp A >, <&macro_release &kp LALT>;
        };

        m_ap_vel_vd: m_ap_vel_vd {
            compatible = "zmk,behavior-macro";
            #binding-cells = <0>;
            wait-ms = <30>;
            tap-ms = <30>;
            bindings = <&macro_press &kp LALT>, <&kp U &kp N0 &kp N2 &kp N7 &kp N0>, <&macro_release &kp LALT>;
        };

        // --- Layer 16: Lateral Approximant (側面接近音) ---

        m_lap_den_vd: m_lap_den_vd {
            compatible = "zmk,behavior-macro";
            #binding-cells = <0>;
            wait-ms = <30>;
            tap-ms = <30>;
            bindings = <&macro_press &kp LALT>, <&kp U &kp N0 &kp N0 &kp N6 &kp C &kp N0 &kp N3 &kp N2 &kp A>, <&macro_release &kp LALT>;
        }; // l̪
        m_lap_alv_vl: m_lap_alv_vl {
            compatible = "zmk,behavior-macro";
            #binding-cells = <0>;
            wait-ms = <30>;
            tap-ms = <30>;
            bindings = <&macro_press &kp LALT>, <&kp U &kp N0 &kp N0 &kp N6 &kp C &kp N0 &kp N3 &kp N2 &kp N5>, <&macro_release &kp LALT>;
        }; // l̥
        m_lap_alv_vd: m_lap_alv_vd {
            compatible = "zmk,behavior-macro";
            #binding-cells = <0>;
            wait-ms = <30>;
            tap-ms = <30>;
            bindings = <&macro_press &kp LALT>, <&kp U &kp N0 &kp N0 &kp N6 &kp C>, <&macro_release &kp LALT>;
        };

        m_lap_ret_vl: m_lap_ret_vl {
            compatible = "zmk,behavior-macro";
            #binding-cells = <0>;
            wait-ms = <30>;
            tap-ms = <30>;
            bindings = <&macro_press &kp LALT>, <&kp N0 &kp N2 &kp N6 &kp D &kp N0 &kp N3 &kp N0 &kp A>, <&macro_release &kp LALT>;
        }; // ɭ̊
        m_lap_ret_vd: m_lap_ret_vd {
            compatible = "zmk,behavior-macro";
            #binding-cells = <0>;
            wait-ms = <30>;
            tap-ms = <30>;
            bindings = <&macro_press &kp LALT>, <&kp N0 &kp N2 &kp N6 &kp D>, <&macro_release &kp LALT>;
        }; // ɭ
        m_lap_pala_vl: m_lap_pala_vl {
            compatible = "zmk,behavior-macro";
            #binding-cells = <0>;
            wait-ms = <30>;
            tap-ms = <30>;
            bindings = <&macro_press &kp LALT>, <&kp N0 &kp N2 &kp N8 &kp E &kp N0 &kp N3 &kp N0 &kp A>, <&macro_release &kp LALT>;
        }; // ʎ̥
        m_lap_pala_vd: m_lap_pala_vd {
            compatible = "zmk,behavior-macro";
            #binding-cells = <0>;
            wait-ms = <30>;
            tap-ms = <30>;
            bindings = <&macro_press &kp LALT>, <&kp N0 &kp N2 &kp N8 &kp E>, <&macro_release &kp LALT>;
        }; // ʎ
        m_lap_vel_vl: m_lap_vel_vl {
            compatible = "zmk,behavior-macro";
            #binding-cells = <0>;
            wait-ms = <30>;
            tap-ms = <30>;
            bindings = <&macro_press &kp LALT>, <&kp N0 &kp N2 &kp N9 &kp F &kp N0 &kp N3 &kp N0 &kp A>, <&macro_release &kp LALT>;
        }; // ʟ̥
        m_lap_vel_vd: m_lap_vel_vd {
            compatible = "zmk,behavior-macro";
            #binding-cells = <0>;
            wait-ms = <30>;
            tap-ms = <30>;
            bindings = <&macro_press &kp LALT>, <&kp N0 &kp N2 &kp N9 &kp F>, <&macro_release &kp LALT>;
        }; // ʟ
        m_lap_uv_vd: m_lap_uv_vd {
            compatible = "zmk,behavior-macro";
            #binding-cells = <0>;
            wait-ms = <30>;
            tap-ms = <30>;
            bindings = <&macro_press &kp LALT>, <&kp N0 &kp N2 &kp N9 &kp F &kp N0 &kp N3 &kp N2 &kp N0>, <&macro_release &kp LALT>;
        }; // ʟ̠
        // --- Layer 17: Tap/Flap (弾き音) ---

        m_tap_bil_vd: m_tap_lab_vd_pre {
            compatible = "zmk,behavior-macro";
            #binding-cells = <0>;
            wait-ms = <30>;
            tap-ms = <30>;
            bindings = <&macro_press &kp LALT>, <&kp N0 &kp N2 &kp C &kp N3 &kp N0 &kp N2 &kp N8 &kp B>, <&macro_release &kp LALT>;
        }; // ⱱ̟
        m_tap_lab_vd: m_tap_lab_vd {
            compatible = "zmk,behavior-macro";
            #binding-cells = <0>;
            wait-ms = <30>;
            tap-ms = <30>;
            bindings = <&macro_press &kp LALT>, <&kp N0 &kp N2 &kp N8 &kp B>, <&macro_release &kp LALT>;
        }; // ⱱ
        m_tap_alv_vl: m_tap_alv_vl {
            compatible = "zmk,behavior-macro";
            #binding-cells = <0>;
            wait-ms = <30>;
            tap-ms = <30>;
            bindings = <&macro_press &kp LALT>, <&kp N0 &kp N2 &kp N7 &kp E &kp N0 &kp N3 &kp N2 &kp N5>, <&macro_release &kp LALT>;
        }; // ɾ̥
        m_tap_alv_vd: m_tap_alv_vd {
            compatible = "zmk,behavior-macro";
            #binding-cells = <0>;
            wait-ms = <30>;
            tap-ms = <30>;
            bindings = <&macro_press &kp LALT>, <&kp N0 &kp N2 &kp N7 &kp E>, <&macro_release &kp LALT>;
        }; // ɾ
        m_tap_ret_vl: m_tap_ret_vl {
            compatible = "zmk,behavior-macro";
            #binding-cells = <0>;
            wait-ms = <30>;
            tap-ms = <30>;
            bindings = <&macro_press &kp LALT>, <&kp N0 &kp N2 &kp N7 &kp D &kp N0 &kp N3 &kp N0 &kp A>, <&macro_release &kp LALT>;
        }; // ɽ̊
        m_tap_ret_vd: m_tap_ret_vd {
            compatible = "zmk,behavior-macro";
            #binding-cells = <0>;
            wait-ms = <30>;
            tap-ms = <30>;
            bindings = <&macro_press &kp LALT>, <&kp N0 &kp N2 &kp N7 &kp D>, <&macro_release &kp LALT>;
        }; // ɽ
        m_tap_uv_vd: m_tap_uv_vd {
            compatible = "zmk,behavior-macro";
            #binding-cells = <0>;
            wait-ms = <30>;
            tap-ms = <30>;
            bindings = <&macro_press &kp LALT>, <&kp N0 &kp N2 &kp N6 &kp N2 &kp N0 &kp N3 &kp N0 &kp N6>, <&macro_release &kp LALT>;
        }; // ɢ̆
        m_tap_epi_vd: m_tap_epi_vd {
            compatible = "zmk,behavior-macro";
            #binding-cells = <0>;
            wait-ms = <30>;
            tap-ms = <30>;
            bindings = <&macro_press &kp LALT>, <&kp N0 &kp N2 &kp A &kp N1 &kp N0 &kp N3 &kp N0 &kp N6>, <&macro_release &kp LALT>;
        }; // ʡ̆
        // --- Layer 18: Lateral Tap/Flap (側面弾き音) ---

        m_ltap_alv_vl: m_ltap_alv_vl {
            compatible = "zmk,behavior-macro";
            #binding-cells = <0>;
            wait-ms = <30>;
            tap-ms = <30>;
            bindings = <&macro_press &kp LALT>, <&kp N0 &kp N2 &kp N7 &kp A &kp N0 &kp N3 &kp N2 &kp N5>, <&macro_release &kp LALT>;
        }; // ɺ̥
        m_ltap_alv_vd: m_ltap_alv_vd {
            compatible = "zmk,behavior-macro";
            #binding-cells = <0>;
            wait-ms = <30>;
            tap-ms = <30>;
            bindings = <&macro_press &kp LALT>, <&kp N0 &kp N2 &kp N7 &kp A>, <&macro_release &kp LALT>;
        }; // ɺ
        m_ltap_ret_vl: m_ltap_ret_vl {
            compatible = "zmk,behavior-macro";
            #binding-cells = <0>;
            wait-ms = <30>;
            tap-ms = <30>;
            bindings = <&macro_press &kp LALT>, <&kp N0 &kp N2 &kp N6 &kp D &kp N0 &kp N3 &kp N0 &kp N6 &kp N0 &kp N3 &kp N0 &kp A>, <&macro_release &kp LALT>;
        }; // ɭ̆ ̥
        m_ltap_ret_vd: m_ltap_ret_vd {
            compatible = "zmk,behavior-macro";
            #binding-cells = <0>;
            wait-ms = <30>;
            tap-ms = <30>;
            bindings = <&macro_press &kp LALT>, <&kp N0 &kp N2 &kp N6 &kp D &kp N0 &kp N3 &kp N0 &kp N6>, <&macro_release &kp LALT>;
        }; // ɭ̆
        m_ltap_pala_vd: m_ltap_pala_vd {
            compatible = "zmk,behavior-macro";
            #binding-cells = <0>;
            wait-ms = <30>;
            tap-ms = <30>;
            bindings = <&macro_press &kp LALT>, <&kp N0 &kp N2 &kp N8 &kp E &kp N0 &kp N3 &kp N0 &kp N6>, <&macro_release &kp LALT>;
        }; // ʎ̆
        m_ltap_vel_vd: m_ltap_vel_vd {
            compatible = "zmk,behavior-macro";
            #binding-cells = <0>;
            wait-ms = <30>;
            tap-ms = <30>;
            bindings = <&macro_press &kp LALT>, <&kp N0 &kp N2 &kp N9 &kp F &kp N0 &kp N3 &kp N0 &kp N6>, <&macro_release &kp LALT>;
        }; // ʟ̆
        // --- Layer 19: Trill (ふるえ音) ---

        m_tr_bil_vl: m_tr_bil_vl {
            compatible = "zmk,behavior-macro";
            #binding-cells = <0>;
            wait-ms = <30>;
            tap-ms = <30>;
            bindings = <&macro_press &kp LALT>, <&kp N0 &kp N2 &kp N9 &kp N9 &kp N0 &kp N3 &kp N2 &kp N5>, <&macro_release &kp LALT>;
        }; // ʙ̥
        m_tr_bil_vd: m_tr_bil_vd {
            compatible = "zmk,behavior-macro";
            #binding-cells = <0>;
            wait-ms = <30>;
            tap-ms = <30>;
            bindings = <&macro_press &kp LALT>, <&kp N0 &kp N2 &kp N9 &kp N9>, <&macro_release &kp LALT>;
        }; // ʙ
        m_tr_alv_vl: m_tr_alv_vl {
            compatible = "zmk,behavior-macro";
            #binding-cells = <0>;
            wait-ms = <30>;
            tap-ms = <30>;
            bindings = <&macro_press &kp LALT>, <&kp U &kp N0 &kp N0 &kp N7 &kp N9 &kp N0 &kp N3 &kp N2 &kp N5>, <&macro_release &kp LALT>;
        }; // r̥
        m_tr_alv_vd: m_tr_alv_vd {
            compatible = "zmk,behavior-macro";
            #binding-cells = <0>;
            wait-ms = <30>;
            tap-ms = <30>;
            bindings = <&macro_press &kp LALT>, <&kp U &kp N0 &kp N0 &kp N7 &kp N9>, <&macro_release &kp LALT>;
        };

        m_tr_palv_vd: m_tr_palv_vd {
            compatible = "zmk,behavior-macro";
            #binding-cells = <0>;
            wait-ms = <30>;
            tap-ms = <30>;
            bindings = <&macro_press &kp LALT>, <&kp U &kp N0 &kp N0 &kp N7 &kp N9 &kp N0 &kp N3 &kp N2 &kp N0>, <&macro_release &kp LALT>;
        }; // r̠
        m_tr_ret_vl: m_tr_ret_vl {
            compatible = "zmk,behavior-macro";
            #binding-cells = <0>;
            wait-ms = <30>;
            tap-ms = <30>;
            bindings = <&macro_press &kp LALT>, <&kp U &kp N0 &kp N0 &kp N7 &kp N9 &kp N0 &kp N3 &kp N6 &kp N1 &kp N0 &kp N2 &kp N7 &kp D &kp N0 &kp N3 &kp N0 &kp A>, <&macro_release &kp LALT>;
        }; // r̥͡ɽ̊
        m_tr_ret_vd: m_tr_ret_vd {
            compatible = "zmk,behavior-macro";
            #binding-cells = <0>;
            wait-ms = <30>;
            tap-ms = <30>;
            bindings = <&macro_press &kp LALT>, <&kp U &kp N0 &kp N0 &kp N7 &kp N9 &kp N0 &kp N3 &kp N6 &kp N1 &kp N0 &kp N2 &kp N7 &kp D>, <&macro_release &kp LALT>;
        }; // r͡ɽ
        m_tr_uv_vl: m_tr_uv_vl {
            compatible = "zmk,behavior-macro";
            #binding-cells = <0>;
            wait-ms = <30>;
            tap-ms = <30>;
            bindings = <&macro_press &kp LALT>, <&kp N0 &kp N2 &kp N8 &kp N0 &kp N0 &kp N3 &kp N2 &kp N5>, <&macro_release &kp LALT>;
        }; // ʀ̥
        m_tr_uv_vd: m_tr_uv_vd {
            compatible = "zmk,behavior-macro";
            #binding-cells = <0>;
            wait-ms = <30>;
            tap-ms = <30>;
            bindings = <&macro_press &kp LALT>, <&kp N0 &kp N2 &kp N8 &kp N0>, <&macro_release &kp LALT>;
        }; // ʀ
        m_tr_epi_vl: m_tr_epi_vl {
            compatible = "zmk,behavior-macro";
            #binding-cells = <0>;
            wait-ms = <30>;
            tap-ms = <30>;
            bindings = <&macro_press &kp LALT>, <&kp N0 &kp N2 &kp N9 &kp C>, <&macro_release &kp LALT>;
        }; // ʜ
        m_tr_epi_vd: m_tr_epi_vd {
            compatible = "zmk,behavior-macro";
            #binding-cells = <0>;
            wait-ms = <30>;
            tap-ms = <30>;
            bindings = <&macro_press &kp LALT>, <&kp N0 &kp N2 &kp A &kp N2>, <&macro_release &kp LALT>;
        }; // ʢ
        // --- Layer 20: Implosive/Clicks (吸着音 / 入破音) ---

        m_im_bil_vl: m_im_bil_vl {
            compatible = "zmk,behavior-macro";
            #binding-cells = <0>;
            wait-ms = <30>;
            tap-ms = <30>;
            bindings = <&macro_press &kp LALT>, <&kp N0 &kp N2 &kp N9 &kp N8>, <&macro_release &kp LALT>;
        }; // ʘ
        m_im_bil_vd: m_im_bil_vd {
            compatible = "zmk,behavior-macro";
            #binding-cells = <0>;
            wait-ms = <30>;
            tap-ms = <30>;
            bindings = <&macro_press &kp LALT>, <&kp N0 &kp N2 &kp N5 &kp N3>, <&macro_release &kp LALT>;
        }; // ɓ
        m_im_den_vl: m_im_den_vl {
            compatible = "zmk,behavior-macro";
            #binding-cells = <0>;
            wait-ms = <30>;
            tap-ms = <30>;
            bindings = <&macro_press &kp LALT>, <&kp N0 &kp N1 &kp C &kp N0>, <&macro_release &kp LALT>;
        }; // ǀ
        m_im_alv_vl: m_im_alv_vl {
            compatible = "zmk,behavior-macro";
            #binding-cells = <0>;
            wait-ms = <30>;
            tap-ms = <30>;
            bindings = <&macro_press &kp LALT>, <&kp N0 &kp N1 &kp C &kp N3>, <&macro_release &kp LALT>;
        }; // ǃ
        m_im_alv_vd: m_im_alv_vd {
            compatible = "zmk,behavior-macro";
            #binding-cells = <0>;
            wait-ms = <30>;
            tap-ms = <30>;
            bindings = <&macro_press &kp LALT>, <&kp N0 &kp N2 &kp N5 &kp N7>, <&macro_release &kp LALT>;
        }; // ɗ
        m_im_ret_vl: m_im_ret_vl {
            compatible = "zmk,behavior-macro";
            #binding-cells = <0>;
            wait-ms = <30>;
            tap-ms = <30>;
            bindings = <&macro_press &kp LALT>, <&kp N0 &kp N2 &kp N0 &kp N3 &kp C>, <&macro_release &kp LALT>;
        }; // ‼︎
        m_im_ret_vd: m_im_ret_vd {
            compatible = "zmk,behavior-macro";
            #binding-cells = <0>;
            wait-ms = <30>;
            tap-ms = <30>;
            bindings = <&macro_press &kp LALT>, <&kp N0 &kp N1 &kp D &kp A &kp N1>, <&macro_release &kp LALT>;
        }; // ᶑ
        m_im_pala_vl: m_im_pala_vl {
            compatible = "zmk,behavior-macro";
            #binding-cells = <0>;
            wait-ms = <30>;
            tap-ms = <30>;
            bindings = <&macro_press &kp LALT>, <&kp N0 &kp N1 &kp C &kp N2>, <&macro_release &kp LALT>;
        }; // ǂ
        m_im_pala_vd: m_im_pala_vd {
            compatible = "zmk,behavior-macro";
            #binding-cells = <0>;
            wait-ms = <30>;
            tap-ms = <30>;
            bindings = <&macro_press &kp LALT>, <&kp N0 &kp N2 &kp N8 &kp N4>, <&macro_release &kp LALT>;
        }; // ʄ
        m_im_vel_vl: m_im_vel_vl {
            compatible = "zmk,behavior-macro";
            #binding-cells = <0>;
            wait-ms = <30>;
            tap-ms = <30>;
            bindings = <&macro_press &kp LALT>, <&kp N0 &kp N1 &kp C &kp N1>, <&macro_release &kp LALT>;
        }; // ǁ
        m_im_vel_vd: m_im_vel_vd {
            compatible = "zmk,behavior-macro";
            #binding-cells = <0>;
            wait-ms = <30>;
            tap-ms = <30>;
            bindings = <&macro_press &kp LALT>, <&kp N0 &kp N2 &kp N6 &kp N0>, <&macro_release &kp LALT>;
        }; // ɠ
        m_im_uv_vd: m_im_uv_vd {
            compatible = "zmk,behavior-macro";
            #binding-cells = <0>;
            wait-ms = <30>;
            tap-ms = <30>;
            bindings = <&macro_press &kp LALT>, <&kp N0 &kp N2 &kp N9 &kp B>, <&macro_release &kp LALT>;
        }; // ʛ
        // --- Layer 21: Lateral Click (側面吸着音) ---

        m_lim_den_vl: m_lim_den_vl {
            compatible = "zmk,behavior-macro";
            #binding-cells = <0>;
            wait-ms = <30>;
            tap-ms = <30>;
            bindings = <&macro_press &kp LALT>, <&kp N0 &kp N1 &kp C &kp N1 &kp N0 &kp N3 &kp N3 &kp N2>, <&macro_release &kp LALT>;
        }; // ǁ̠
        // --- Layer 8: Close (狭母音) ---

        v_cl_fr_un: v_cl_fr_un {
            compatible = "zmk,behavior-macro";
            #binding-cells = <0>;
            wait-ms = <30>;
            tap-ms = <30>;
            bindings = <&macro_press &kp LALT>, <&kp U &kp N0 &kp N0 &kp N6 &kp N9>, <&macro_release &kp LALT>;
        }; // i
        v_cl_fr_ro: v_cl_fr_ro {
            compatible = "zmk,behavior-macro";
            #binding-cells = <0>;
            wait-ms = <30>;
            tap-ms = <30>;
            bindings = <&macro_press &kp LALT>, <&kp U &kp N0 &kp N0 &kp N7 &kp N9>, <&macro_release &kp LALT>;
        }; // y
        v_cl_ce_un: v_cl_ce_un {
            compatible = "zmk,behavior-macro";
            #binding-cells = <0>;
            wait-ms = <30>;
            tap-ms = <30>;
            bindings = <&macro_press &kp LALT>, <&kp N0 &kp N2 &kp N6 &kp N8>, <&macro_release &kp LALT>;
        }; // ɨ
        v_cl_ce_ro: v_cl_ce_ro {
            compatible = "zmk,behavior-macro";
            #binding-cells = <0>;
            wait-ms = <30>;
            tap-ms = <30>;
            bindings = <&macro_press &kp LALT>, <&kp N0 &kp N2 &kp N8 &kp N9>, <&macro_release &kp LALT>;
        }; // ʉ
        v_cl_ba_un: v_cl_ba_un {
            compatible = "zmk,behavior-macro";
            #binding-cells = <0>;
            wait-ms = <30>;
            tap-ms = <30>;
            bindings = <&macro_press &kp LALT>, <&kp N0 &kp N2 &kp N6 &kp F>, <&macro_release &kp LALT>;
        }; // ɯ
        v_cl_ba_ro: v_cl_ba_ro {
            compatible = "zmk,behavior-macro";
            #binding-cells = <0>;
            wait-ms = <30>;
            tap-ms = <30>;
            bindings = <&macro_press &kp LALT>, <&kp U &kp N0 &kp N0 &kp N7 &kp N5>, <&macro_release &kp LALT>;
        }; // u
        // --- Layer 11: Near-close (広めの狭母音) ---

        v_nc_fr_un: v_nc_fr_un {
            compatible = "zmk,behavior-macro";
            #binding-cells = <0>;
            wait-ms = <30>;
            tap-ms = <30>;
            bindings = <&macro_press &kp LALT>, <&kp N0 &kp N2 &kp N6 &kp A>, <&macro_release &kp LALT>;
        }; // ɪ
        v_nc_fr_ro: v_nc_fr_ro {
            compatible = "zmk,behavior-macro";
            #binding-cells = <0>;
            wait-ms = <30>;
            tap-ms = <30>;
            bindings = <&macro_press &kp LALT>, <&kp N0 &kp N2 &kp N8 &kp F>, <&macro_release &kp LALT>;
        }; // ʏ
        v_nc_ce_un: v_nc_ce_un {
            compatible = "zmk,behavior-macro";
            #binding-cells = <0>;
            wait-ms = <30>;
            tap-ms = <30>;
            bindings = <&macro_press &kp LALT>, <&kp N0 &kp N2 &kp N6 &kp N8 &kp N0 &kp N3 &kp N1 &kp E>, <&macro_release &kp LALT>;
        }; // ɨ̞
        v_nc_ce_ro: v_nc_ce_ro {
            compatible = "zmk,behavior-macro";
            #binding-cells = <0>;
            wait-ms = <30>;
            tap-ms = <30>;
            bindings = <&macro_press &kp LALT>, <&kp N0 &kp N2 &kp N8 &kp N9 &kp N0 &kp N3 &kp N1 &kp E>, <&macro_release &kp LALT>;
        }; // ʉ̞
        v_nc_ba_un: v_nc_ba_un {
            compatible = "zmk,behavior-macro";
            #binding-cells = <0>;
            wait-ms = <30>;
            tap-ms = <30>;
            bindings = <&macro_press &kp LALT>, <&kp N0 &kp N2 &kp N6 &kp F &kp N0 &kp N3 &kp N1 &kp E>, <&macro_release &kp LALT>;
        }; // ɯ̞
        v_nc_ba_ro: v_nc_ba_ro {
            compatible = "zmk,behavior-macro";
            #binding-cells = <0>;
            wait-ms = <30>;
            tap-ms = <30>;
            bindings = <&macro_press &kp LALT>, <&kp N0 &kp N2 &kp N8 &kp A>, <&macro_release &kp LALT>;
        }; // ʊ
        // --- Layer 9: Close-mid (半狭母音) ---

        v_cm_fr_un: v_cm_fr_un {
            compatible = "zmk,behavior-macro";
            #binding-cells = <0>;
            wait-ms = <30>;
            tap-ms = <30>;
            bindings = <&macro_press &kp LALT>, <&kp N0 &kp N0 &kp N6 &kp N5>, <&macro_release &kp LALT>;
        }; // e
        v_cm_fr_ro: v_cm_fr_ro {
            compatible = "zmk,behavior-macro";
            #binding-cells = <0>;
            wait-ms = <30>;
            tap-ms = <30>;
            bindings = <&macro_press &kp LALT>, <&kp N0 &kp F &kp N8>, <&macro_release &kp LALT>;
        }; // ø
        v_cm_ce_un: v_cm_ce_un {
            compatible = "zmk,behavior-macro";
            #binding-cells = <0>;
            wait-ms = <30>;
            tap-ms = <30>;
            bindings = <&macro_press &kp LALT>, <&kp N0 &kp N2 &kp N5 &kp N8>, <&macro_release &kp LALT>;
        }; // ɘ
        v_cm_ce_ro: v_cm_ce_ro {
            compatible = "zmk,behavior-macro";
            #binding-cells = <0>;
            wait-ms = <30>;
            tap-ms = <30>;
            bindings = <&macro_press &kp LALT>, <&kp N0 &kp N2 &kp N7 &kp N5>, <&macro_release &kp LALT>;
        }; // ɵ
        v_cm_ba_un: v_cm_ba_un {
            compatible = "zmk,behavior-macro";
            #binding-cells = <0>;
            wait-ms = <30>;
            tap-ms = <30>;
            bindings = <&macro_press &kp LALT>, <&kp N0 &kp N2 &kp N6 &kp N4>, <&macro_release &kp LALT>;
        }; // ɤ
        v_cm_ba_ro: v_cm_ba_ro {
            compatible = "zmk,behavior-macro";
            #binding-cells = <0>;
            wait-ms = <30>;
            tap-ms = <30>;
            bindings = <&macro_press &kp LALT>, <&kp N0 &kp N0 &kp N6 &kp F>, <&macro_release &kp LALT>;
        }; // o
        // --- Layer 15: Mid (中央母音) ---

        v_mi_fr_un: v_mi_fr_un {
            compatible = "zmk,behavior-macro";
            #binding-cells = <0>;
            wait-ms = <30>;
            tap-ms = <30>;
            bindings = <&macro_press &kp LALT>, <&kp N0 &kp N0 &kp N6 &kp N5 &kp N0 &kp N3 &kp N1 &kp E>, <&macro_release &kp LALT>;
        }; // e̞
        v_mi_fr_ro: v_mi_fr_ro {
            compatible = "zmk,behavior-macro";
            #binding-cells = <0>;
            wait-ms = <30>;
            tap-ms = <30>;
            bindings = <&macro_press &kp LALT>, <&kp N0 &kp F &kp N8 &kp N0 &kp N3 &kp N1 &kp E>, <&macro_release &kp LALT>;
        }; // ø̞
        v_mi_ce_un: v_mi_ce_un {
            compatible = "zmk,behavior-macro";
            #binding-cells = <0>;
            wait-ms = <30>;
            tap-ms = <30>;
            bindings = <&macro_press &kp LALT>, <&kp N0 &kp N2 &kp N5 &kp N9>, <&macro_release &kp LALT>;
        }; // ə
        v_mi_ce_ro: v_mi_ce_ro {
            compatible = "zmk,behavior-macro";
            #binding-cells = <0>;
            wait-ms = <30>;
            tap-ms = <30>;
            bindings = <&macro_press &kp LALT>, <&kp N0 &kp N2 &kp N7 &kp N5 &kp N0 &kp N3 &kp N1 &kp E>, <&macro_release &kp LALT>;
        }; // ɵ̞
        v_mi_ba_un: v_mi_ba_un {
            compatible = "zmk,behavior-macro";
            #binding-cells = <0>;
            wait-ms = <30>;
            tap-ms = <30>;
            bindings = <&macro_press &kp LALT>, <&kp N0 &kp N2 &kp N6 &kp N4 &kp N0 &kp N3 &kp N1 &kp E>, <&macro_release &kp LALT>;
        }; // ɤ̞
        v_mi_ba_ro: v_mi_ba_ro {
            compatible = "zmk,behavior-macro";
            #binding-cells = <0>;
            wait-ms = <30>;
            tap-ms = <30>;
            bindings = <&macro_press &kp LALT>, <&kp N0 &kp N0 &kp N6 &kp F &kp N0 &kp N3 &kp N1 &kp E>, <&macro_release &kp LALT>;
        }; // o̞
        // --- Layer 17: Open-mid (半広母音) ---

        v_om_fr_un: v_om_fr_un {
            compatible = "zmk,behavior-macro";
            #binding-cells = <0>;
            wait-ms = <30>;
            tap-ms = <30>;
            bindings = <&macro_press &kp LALT>, <&kp N0 &kp N2 &kp N5 &kp B>, <&macro_release &kp LALT>;
        }; // ɛ
        v_om_fr_ro: v_om_fr_ro {
            compatible = "zmk,behavior-macro";
            #binding-cells = <0>;
            wait-ms = <30>;
            tap-ms = <30>;
            bindings = <&macro_press &kp LALT>, <&kp N0 &kp N1 &kp N5 &kp N3>, <&macro_release &kp LALT>;
        }; // œ
        v_om_ce_un: v_om_ce_un {
            compatible = "zmk,behavior-macro";
            #binding-cells = <0>;
            wait-ms = <30>;
            tap-ms = <30>;
            bindings = <&macro_press &kp LALT>, <&kp N0 &kp N2 &kp N5 &kp C>, <&macro_release &kp LALT>;
        }; // ɜ
        v_om_ce_ro: v_om_ce_ro {
            compatible = "zmk,behavior-macro";
            #binding-cells = <0>;
            wait-ms = <30>;
            tap-ms = <30>;
            bindings = <&macro_press &kp LALT>, <&kp N0 &kp N2 &kp N9 &kp A>, <&macro_release &kp LALT>;
        }; // ɞ
        v_om_ba_un: v_om_ba_un {
            compatible = "zmk,behavior-macro";
            #binding-cells = <0>;
            wait-ms = <30>;
            tap-ms = <30>;
            bindings = <&macro_press &kp LALT>, <&kp N0 &kp N2 &kp N8 &kp C>, <&macro_release &kp LALT>;
        }; // ʌ
        v_om_ba_ro: v_om_ba_ro {
            compatible = "zmk,behavior-macro";
            #binding-cells = <0>;
            wait-ms = <30>;
            tap-ms = <30>;
            bindings = <&macro_press &kp LALT>, <&kp N0 &kp N2 &kp N5 &kp N4>, <&macro_release &kp LALT>;
        }; // ɔ
        // --- Layer 19: Near-open (狭めの広母音) ---

        v_no_fr_un: v_no_fr_un {
            compatible = "zmk,behavior-macro";
            #binding-cells = <0>;
            wait-ms = <30>;
            tap-ms = <30>;
            bindings = <&macro_press &kp LALT>, <&kp N0 &kp E &kp N6>, <&macro_release &kp LALT>;
        }; // æ
        v_no_fr_ro: v_no_fr_ro {
            compatible = "zmk,behavior-macro";
            #binding-cells = <0>;
            wait-ms = <30>;
            tap-ms = <30>;
            bindings = <&macro_press &kp LALT>, <&kp N0 &kp N1 &kp N5 &kp N3 &kp N0 &kp N3 &kp N1 &kp E>, <&macro_release &kp LALT>;
        }; // œ̞
        v_no_ce_un: v_no_ce_un {
            compatible = "zmk,behavior-macro";
            #binding-cells = <0>;
            wait-ms = <30>;
            tap-ms = <30>;
            bindings = <&macro_press &kp LALT>, <&kp N0 &kp N2 &kp N5 &kp N0>, <&macro_release &kp LALT>;
        }; // ɐ
        v_no_ce_ro: v_no_ce_ro {
            compatible = "zmk,behavior-macro";
            #binding-cells = <0>;
            wait-ms = <30>;
            tap-ms = <30>;
            bindings = <&macro_press &kp LALT>, <&kp N0 &kp N2 &kp N9 &kp A &kp N0 &kp N3 &kp N1 &kp E>, <&macro_release &kp LALT>;
        }; // ɞ̞
        v_no_ba_un: v_no_ba_un {
            compatible = "zmk,behavior-macro";
            #binding-cells = <0>;
            wait-ms = <30>;
            tap-ms = <30>;
            bindings = <&macro_press &kp LALT>, <&kp N0 &kp N2 &kp N5 &kp N1 &kp N0 &kp N3 &kp N1 &kp D>, <&macro_release &kp LALT>;
        }; // ɑ̝
        v_no_ba_ro: v_no_ba_ro {
            compatible = "zmk,behavior-macro";
            #binding-cells = <0>;
            wait-ms = <30>;
            tap-ms = <30>;
            bindings = <&macro_press &kp LALT>, <&kp N0 &kp N2 &kp N5 &kp N2 &kp N0 &kp N3 &kp N1 &kp D>, <&macro_release &kp LALT>;
        }; // ɒ̝
        // --- Layer 20: Open (広母音) ---

        v_op_fr_un: v_op_fr_un {
            compatible = "zmk,behavior-macro";
            #binding-cells = <0>;
            wait-ms = <30>;
            tap-ms = <30>;
            bindings = <&macro_press &kp LALT>, <&kp N0 &kp N0 &kp N6 &kp N1>, <&macro_release &kp LALT>;
        }; // a
        v_op_fr_ro: v_op_fr_ro {
            compatible = "zmk,behavior-macro";
            #binding-cells = <0>;
            wait-ms = <30>;
            tap-ms = <30>;
            bindings = <&macro_press &kp LALT>, <&kp N0 &kp N2 &kp N7 &kp N6>, <&macro_release &kp LALT>;
        }; // ɶ
        v_op_ce_un: v_op_ce_un {
            compatible = "zmk,behavior-macro";
            #binding-cells = <0>;
            wait-ms = <30>;
            tap-ms = <30>;
            bindings = <&macro_press &kp LALT>, <&kp N0 &kp N0 &kp N6 &kp N1 &kp N0 &kp N3 &kp N0 &kp N8>, <&macro_release &kp LALT>;
        }; // ä
        v_op_ce_ro: v_op_ce_ro {
            compatible = "zmk,behavior-macro";
            #binding-cells = <0>;
            wait-ms = <30>;
            tap-ms = <30>;
            bindings = <&macro_press &kp LALT>, <&kp N0 &kp N2 &kp N5 &kp N2 &kp N0 &kp N3 &kp N0 &kp N8>, <&macro_release &kp LALT>;
        }; // ɒ̈
        v_op_ba_un: v_op_ba_un {
            compatible = "zmk,behavior-macro";
            #binding-cells = <0>;
            wait-ms = <30>;
            tap-ms = <30>;
            bindings = <&macro_press &kp LALT>, <&kp N0 &kp N2 &kp N5 &kp N1>, <&macro_release &kp LALT>;
        }; // ɑ
        v_op_ba_ro: v_op_ba_ro {
            compatible = "zmk,behavior-macro";
            #binding-cells = <0>;
            wait-ms = <30>;
            tap-ms = <30>;
            bindings = <&macro_press &kp LALT>, <&kp N0 &kp N2 &kp N5 &kp N2>, <&macro_release &kp LALT>;
        }; // ɒ
    };

    behaviors {
        scroll_up_down: behavior_sensor_rotate_mouse_wheel_up_down {
            compatible = "zmk,behavior-sensor-rotate";
            #sensor-binding-cells = <0>;
            bindings = <&msc SCRL_DOWN &msc SCRL_UP>;
            tap-ms = <20>;
        };

        // 名前を lt_ipa から ipa_sw に変更、
        // もしくは ipa_sw というラベルを付与する

        ipa_sw: lt_ipa {
            compatible = "zmk,behavior-hold-tap";
            #binding-cells = <2>;
            tapping-term-ms = <150>;
            flavor = "hold-preferred";
            bindings = <&mo>, <&kp>;
 // レイヤー(mo)とキー(kp)を組み合わせる標準的な設定
        };

        lt_NUM: lt_NUM {
            compatible = "zmk,behavior-hold-tap";
            #binding-cells = <2>;
            tapping-term-ms = <200>;
            bindings = <&mo>, <&kp>;
        };
    };

    keymap {
        compatible = "zmk,keymap";

        default_layer {
            bindings = <
&kp Q             &kp W               &kp E             &kp R             &kp T                                                      &kp Y                  &kp U         &lt 5 I    &kp O    &kp P
&kp A             &kp S               &kp D             &kp F             &kp G             &mkp MB1                &lt_NUM 6 EQUAL  &kp H                  &kp J         &kp K      &kp L    &lt 5 ASTRK
&kp Z             &kp X               &kp C             &kp V             &kp B             &mt LEFT_SHIFT MINUS      &ipa_sw 20 BSLH  &ipa_sw 7 N            &ipa_sw 20 M  &mt LEFT_GUI COMMA  &kp DOT  &kp SEMICOLON
&ipa_sw 8 K_COPY  &ipa_sw 11 K_PASTE  &ipa_sw 9 K_UNDO  &ipa_sw 15 LANG2  &ipa_sw 17 SPACE  &ipa_sw 19 LANG1        &mt BACKSPACE BACKSPACE    &mt RIGHT_SHIFT ENTER                                    &kp DEL
            >;

            sensor-bindings = <&scroll_up_down>;
        };

        SYMBOLS {
            bindings = <
&kp ESCAPE  &kp AMPERSAND    &kp ASTERISK  &kp LEFT_PARENTHESIS  &kp RIGHT_PARENTHESIS                      &kp LEFT_PARENTHESIS  &kp RIGHT_PARENTHESIS  &trans         &trans             &trans
&kp TILDE   &kp DOLLAR       &kp PERCENT   &kp CARET             &trans                 &trans      &trans  &kp LEFT_BRACE        &kp RIGHT_BRACE        &kp SEMICOLON  &kp SINGLE_QUOTE   &kp BACKSLASH
&kp GRAVE   &kp EXCLAMATION  &kp AT_SIGN   &kp HASH              &trans                 &trans      &trans  &kp LEFT_BRACKET      &kp RIGHT_BRACKET      &kp COLON      &kp DOUBLE_QUOTES  &kp PIPE
&trans      &trans           &trans        &trans                &trans                 &trans      &trans  &trans                                                                         &trans
            >;
        };

        NUM {
            bindings = <
&kp MINUS  &kp N7        &kp N7        &kp N9        &kp PERIOD                                     &kp LEFT_PARENTHESIS  &kp RIGHT_PARENTHESIS  &trans  &kp UP_ARROW  &trans
&kp SLASH  &kp NUMBER_4  &kp N5        &kp NUMBER_6  &kp ASTERISK  &kp LC(LA(PERCENT))      &trans  &kp LEFT_BRACE        &kp RIGHT_BRACE        &kp LEFT_ARROW  &kp DOWN_ARROW  &kp RIGHT_ARROW
&kp N0     &kp N1        &kp NUMBER_2  &kp NUMBER_3  &kp PLUS      &kp EQUAL                &trans  &kp LEFT_BRACKET      &kp RIGHT_BRACKET      &trans  &trans  &trans
&trans     &trans        &trans        &trans        &trans        &trans                   &trans  &trans                                                       &trans
            >;
        };

        ARROW {
            bindings = <
&kp LG(LEFT_ARROW)  &kp LC(LS(TAB))         &kp UP_ARROW    &kp LC(TAB)              &kp LG(RIGHT_ARROW)                      &kp LG(LEFT_ARROW)  &kp LS(LC(TAB))         &kp UP_ARROW    &kp LC(TAB)              &trans
&kp HOME            &kp LEFT_ARROW          &kp DOWN_ARROW  &kp RIGHT_ARROW          &kp END              &trans      &trans  &kp HOME            &kp LEFT_ARROW          &kp DOWN_ARROW  &kp RIGHT_ARROW          &kp END
&kp LEFT_SHIFT      &kp LG(LC(LEFT_ARROW))  &trans          &kp LG(LC(RIGHT_ARROW))  &trans               &trans      &trans  &trans              &kp LC(LG(LEFT_ARROW))  &trans          &kp LC(LG(RIGHT_ARROW))  &trans
&trans              &trans                  &trans          &trans                   &trans               &trans      &trans  &trans                                                                               &trans
            >;

            sensor-bindings = <&inc_dec_kp LC(PAGE_UP) LC(PAGE_DOWN)>;
        };

        MOUSE {
            bindings = <
&trans  &trans  &trans  &trans  &trans                                &trans           &trans    &kp LC(T)  &trans    &trans
&trans  &trans  &trans  &trans  &trans         &trans      &kp LC(V)  &kp LC(LS(TAB))  &mkp MB1  &mkp MB3   &mkp MB2  &kp LC(TAB)
&trans  &trans  &trans  &trans  &m_nsa_bil_vd  &trans      &kp LC(C)  &trans           &mkp MB4  &kp LC(W)  &mkp MB5  &trans
&trans  &trans  &trans  &trans  &trans         &trans      &trans     &trans                                          &trans
            >;
        };

        SCROLL {
            bindings = <
&trans  &trans  &trans  &trans  &trans                            &trans  &trans    &trans  &trans  &trans
&trans  &trans  &trans  &trans  &trans        &trans      &trans  &trans  &mkp MB1  &trans  &trans  &trans
&trans  &trans  &trans  &trans  &trans  &trans      &trans  &trans  &trans    &trans  &trans  &trans
&trans  &trans  &trans  &trans  &trans        &trans      &trans  &trans                            &trans
            >;
        };
    };
};
